AUTOSAR XML (schema 4-2-1)
# Copyright (c) 2017 Vector Informatik GmbH.
# License is restricted to the usage with CBD1601056 (D00) for MSR_Ford_SLP1.
# Please contact Vector Informatik whenever you need further information concerning the license conditions.
standard types defined: boolean, uint16, uint32, uint8
package /VehicleProject
  system System
package /TP
  can tp config HS2_CAN: communication-cluster=HS2_CAN, can-tp-ecu{cycle-time-main-function=0.005, ecu-instance=PSCM}
    can tp channel TPCH: channel-id=0, channel-mode=FULL-DUPLEX-MODE
    can-tp-connection addressing-format=STANDARD, can-tp-channel=TPCH, data-pdu=TesterFunctionalReq_H2_Tp_oHS2_CAN, receiver=TN_PSCM, ta-type=FUNCTIONAL, tp-sdu=TesterFunctionalReq_H2_oHS2_CAN, transmitter=TN_TSTR:
      ident TesterFunctionalReq_H2_oTN_TSTR
    can-tp-connection addressing-format=STANDARD, can-tp-channel=TPCH, data-pdu=TesterPhysicalReqPSCM_Tp_oHS2_CAN, flow-control-pdu=TesterPhysicalResPSCM_Tp_oHS2_CAN, receiver=TN_PSCM, ta-type=PHYSICAL, tp-sdu=TesterPhysicalReqPSCM_oHS2_CAN, transmitter=TN_TSTR:
      ident TesterPhysicalReqPSCM_oTN_PSCM
    can-tp-connection addressing-format=STANDARD, can-tp-channel=TPCH, data-pdu=TesterPhysicalResPSCM_Tp_oHS2_CAN, flow-control-pdu=TesterPhysicalReqPSCM_Tp_oHS2_CAN, receiver=TN_TSTR, ta-type=PHYSICAL, tp-sdu=TesterPhysicalResPSCM_oHS2_CAN, transmitter=TN_PSCM:
      ident TesterPhysicalResPSCM_oTN_PSCM
    can tp node TN_PSCM: connector=CN_HS2_CAN
    can tp node TN_TSTR
package /Cluster
  can cluster HS2_CAN: baudrate=500000, protocol-name=CAN  # Y2016_CGEA1.3_CMDB_B_v16.05_HS2 | CGEA1.3 HS2 CAN Network
    can physical channel CHNL: comm-connectors=CN_HS2_CAN
      frame ABS_AutoSar_Network_Mgmt_oHS2_CAN: id 0x596, to PSCM, frame-length=8, can-addressing-mode=STANDARD
        nm pdu ABS_AutoSar_Network_Mgmt_oHS2_CAN: length=8, unused-bit-pattern=0
      frame ABS_BrkBst_Data_oHS2_CAN: id 0x4B0, to PSCM, frame-length=8, can-addressing-mode=STANDARD
        pdu ABS_BrkBst_Data_oHS2_CAN: length=8, minimum-delay=0.01, transmission-mode-false-timing=cyclic-timing={time-offset=0, time-period=0.02}, transmission-mode-true-timing=cyclic-timing={time-offset=0, time-period=0.02}, unused-bit-pattern=0
          signal YawStabilityIndex_oABS_BrkBst_Data_oHS2_CAN: start 0, 9 bit, big-endian, init-value=256, base-type=uint16, compu {510=Cx1FE_NoDataExists, 511=Cx1FF_Fault, phys=raw-256 for raw 0..511; unit %}, unit=%, transfer-property=PENDING, to PSCM
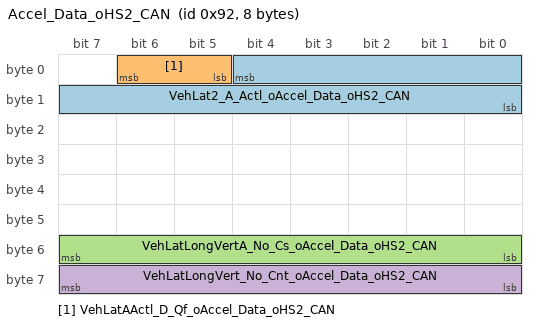
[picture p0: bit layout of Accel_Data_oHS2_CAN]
      frame Accel_Data_oHS2_CAN: id 0x92, to PSCM, frame-length=8, can-addressing-mode=STANDARD
        pdu Accel_Data_oHS2_CAN: length=8, minimum-delay=0, transmission-mode-false-timing=cyclic-timing={time-offset=0, time-period=0.01}, transmission-mode-true-timing=cyclic-timing={time-offset=0, time-period=0.01}, unused-bit-pattern=0
          signal VehLat2_A_Actl_oAccel_Data_oHS2_CAN: start 4, 13 bit, big-endian, init-value=8190, base-type=uint16, compu {8190=Cx1FFE_NoDataExists, 8191=Cx1FFF_Faulty, phys=raw*0.01-40 for raw 0..8191; unit m/s^2} "Source signal range: [0,8189]", unit=m/s^2, transfer-property=PENDING, to PSCM
          signal VehLatAActl_D_Qf_oAccel_Data_oHS2_CAN: start 6, 2 bit, big-endian, init-value=1, base-type=uint8, compu {0..3=RANGE, 0=Cx0_Faulty, 1=Cx1_No_Data_Exists, 2=Cx2_Not_Within_Specifications, 3=Cx3_OK; unit SED}, unit=SED, transfer-property=PENDING, to PSCM
          signal VehLatLongVertA_No_Cs_oAccel_Data_oHS2_CAN: start 55, 8 bit, big-endian, init-value=0, base-type=uint8, compu {0..255=RANGE; unit Unitless}, unit=Unitless, transfer-property=PENDING, to PSCM
          signal VehLatLongVert_No_Cnt_oAccel_Data_oHS2_CAN: start 63, 8 bit, big-endian, init-value=0, base-type=uint8, compu {0..255=RANGE; unit Unitless}, unit=Unitless, transfer-property=PENDING, to PSCM
      frame ActiveFrontSteering_Stat2_oHS2_CAN: id 0x8A, to PSCM, frame-length=8, can-addressing-mode=STANDARD
        pdu ActiveFrontSteering_Stat2_oHS2_CAN: length=8, minimum-delay=0, transmission-mode-false-timing=cyclic-timing={time-offset=0, time-period=0.01}, transmission-mode-true-timing=cyclic-timing={time-offset=0, time-period=0.01}, unused-bit-pattern=0
          signal SteWhlRelCalib_An_Sns_oActiveFrontSteering_Stat2_oHS2_CAN: start 15, 15 bit, big-endian, init-value=0, base-type=uint16, compu {32766=Cx7FFE_NoDataExists, 32767=Cx7FFF_Fault, phys=raw*0.1-1600 for raw 0..32767; unit deg} "Source signal range: [0,32765]", unit=deg, transfer-property=PENDING, to PSCM  # Signal is not transmitted on vehicles where PSCM is transmitting the message that contains this signal. Signal data set to 0x0 for ABS only vehicle option content
      frame Battery_Mgmt_2_HS2_oHS2_CAN: id 0x42C, to PSCM, frame-length=8, can-addressing-mode=STANDARD
        pdu Battery_Mgmt_2_HS2_oHS2_CAN: length=8, minimum-delay=0.02, transmission-mode-false-timing={cyclic-timing={time-offset=0, time-period=0.1}, event-controlled-timing={number-of-repetitions=0, repetition-period=0}}, transmission-mode-true-timing={cyclic-timing={time-offset=0, time-period=0.1}, event-controlled-timing={number-of-repetitions=0, repetition-period=0}}, unused-bit-pattern=0
          signal PwSysULoFalt_D_Stat_oBattery_Mgmt_2_HS2_oHS2_CAN: start 12, 4 bit, big-endian, init-value=0, base-type=uint8, compu {0..15=RANGE, 0=Cx0_No_Fault, 1=Cx1_Cluster_Proveout, 2=Cx2_Fault_Nonspecific, 3=Cx3_Fault_ReducedOutput, 4=Cx4_Fault_NoOutput, 5=Cx5_Overvoltage, 6=Cx6_LowBatt1_Warning, 7=Cx7_LowBatt2_PowerSaveMode, 8=Cx8_LowBattVoltDuringPwSrcOn, 9=Cx9_BattMonitoringSensorFault, 10=CxA_Not_Used_2, 11=CxB_Not_Used_3, 12=CxC_Not_Used_4, 13=CxD_PSS_Shed2_Contin, 14=CxE_LowBatterySOC, 15=CxF_Not_Used_6; unit SED}, unit=SED, transfer-property=TRIGGERED-ON-CHANGE-WITHOUT-REPETITION, to PSCM
      frame Body_Info_4_HS2_oHS2_CAN: id 0x242, to PSCM, frame-length=8, can-addressing-mode=STANDARD
        pdu Body_Info_4_HS2_oHS2_CAN: length=8, minimum-delay=0.02, transmission-mode-false-timing={cyclic-timing={time-offset=0, time-period=0.1}, event-controlled-timing={number-of-repetitions=0, repetition-period=0}}, transmission-mode-true-timing={cyclic-timing={time-offset=0, time-period=0.1}, event-controlled-timing={number-of-repetitions=0, repetition-period=0}}, unused-bit-pattern=0
          signal BattULo_U_Actl_oBody_Info_4_HS2_oHS2_CAN: start 39, 8 bit, big-endian, init-value=255, base-type=uint8, compu {255=CxFF_Fault, phys=raw*0.0625 for raw 0..255; unit volt} "Source signal range: [0,254]", unit=volt, transfer-property=PENDING, to PSCM
      frame BodyEngGateway_2_HS2_oHS2_CAN: id 0x431, to PSCM, frame-length=8, can-addressing-mode=STANDARD
        pdu BodyEngGateway_2_HS2_oHS2_CAN: length=8, minimum-delay=0.02, transmission-mode-false-timing={cyclic-timing={time-offset=0.1, time-period=1}, event-controlled-timing={number-of-repetitions=0, repetition-period=0}}, transmission-mode-true-timing={cyclic-timing={time-offset=0.1, time-period=1}, event-controlled-timing={number-of-repetitions=0, repetition-period=0}}, unused-bit-pattern=0
          signal SteEffort_D_Rq_oBodyEngGateway_2_HS2_oHS2_CAN: start 52, 3 bit, big-endian, init-value=0, base-type=uint8, compu {0..7=RANGE, 0=Cx0_Normal, 1=Cx1_Sport, 2=Cx2_Comfort, 3=Cx3_SpecialMode_1, 4=Cx4_SpecialMode_2, 5=Cx5_NotUsed_1, 6=Cx6_NotUsed_2, 7=Cx7_NotUsed_3; unit SED}, unit=SED, transfer-property=TRIGGERED-ON-CHANGE-WITHOUT-REPETITION, update-indication-bit-position=40, to PSCM
      frame BodyInfo_3_HS2_oHS2_CAN: id 0x3B3, to PSCM, frame-length=8, can-addressing-mode=STANDARD
        pdu BodyInfo_3_HS2_oHS2_CAN: length=8, minimum-delay=0.02, unused-bit-pattern=0
          signal Ignition_Status_oBodyInfo_3_HS2_oHS2_CAN: start 7, 4 bit, big-endian, init-value=0, base-type=uint8, compu {0..15=RANGE, 0=Cx0_Unknown, 1=Cx1_Off, 2=Cx2_Accessory, 4=Cx4_Run, 8=Cx8_Start, 15=CxF_Invalid; unit SED}, unit=SED, transfer-property=PENDING, to PSCM
          signal PrkBrkActv_B_Actl_oBodyInfo_3_HS2_oHS2_CAN: start 55, 1 bit, big-endian, init-value=0, base-type=boolean, compu {0..1=RANGE, 0=Cx0_Inactive, 1=Cx1_Active; unit SED}, unit=SED, transfer-property=PENDING, to PSCM  # Signal not transmitted on vehicles with electric park brake.
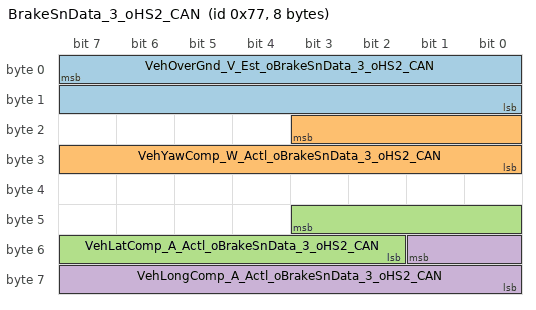
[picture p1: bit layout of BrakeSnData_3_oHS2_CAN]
      frame BrakeSnData_3_oHS2_CAN: id 0x77, to PSCM, frame-length=8, can-addressing-mode=STANDARD
        pdu BrakeSnData_3_oHS2_CAN: length=8, minimum-delay=0.01, transmission-mode-false-timing=cyclic-timing={time-offset=0, time-period=0.02}, transmission-mode-true-timing=cyclic-timing={time-offset=0, time-period=0.02}, unused-bit-pattern=0
          signal VehOverGnd_V_Est_oBrakeSnData_3_oHS2_CAN: start 7, 16 bit, big-endian, init-value=0, base-type=uint16, compu {65534=CxFFFE_Unknown, 65535=CxFFFF_Invalid, phys=raw*0.01 for raw 0..65535; unit kph} "Source signal range: [0,65533]", unit=kph, transfer-property=PENDING, to PSCM
          signal VehYawComp_W_Actl_oBrakeSnData_3_oHS2_CAN: start 19, 12 bit, big-endian, init-value=4094, base-type=uint16, compu {4094=CxFFE_NoDataExists, 4095=CxFFF_Fault, phys=raw*0.03663-75 for raw 0..4095; unit deg/s} "Source signal range: [0,4093]", unit=deg/s, transfer-property=PENDING, to PSCM
          signal VehLatComp_A_Actl_oBrakeSnData_3_oHS2_CAN: start 43, 10 bit, big-endian, init-value=1022, base-type=uint16, compu {1022=Cx3FE_NoDataExists, 1023=Cx3FF_Fault, phys=raw*0.035-17.9 for raw 0..1023; unit m/s^2} "Source signal range: [0,1021]", unit=m/s^2, transfer-property=PENDING, to PSCM
          signal VehLongComp_A_Actl_oBrakeSnData_3_oHS2_CAN: start 49, 10 bit, big-endian, init-value=1022, base-type=uint16, compu {1022=Cx3FE_NoDataExists, 1023=Cx3FF_Fault, phys=raw*0.035-17.9 for raw 0..1023; unit m/s^2} "Source signal range: [0,1021]", unit=m/s^2, transfer-property=PENDING, to PSCM
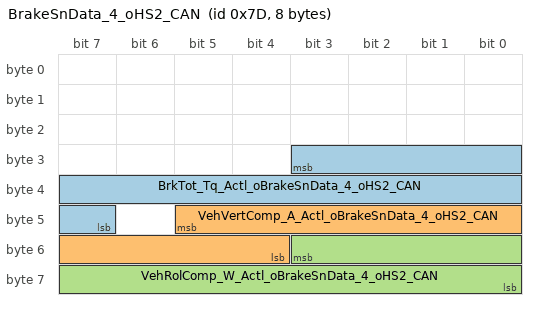
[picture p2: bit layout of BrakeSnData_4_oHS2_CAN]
      frame BrakeSnData_4_oHS2_CAN: id 0x7D, to PSCM, frame-length=8, can-addressing-mode=STANDARD
        pdu BrakeSnData_4_oHS2_CAN: length=8, minimum-delay=0.01, transmission-mode-false-timing=cyclic-timing={time-offset=0, time-period=0.02}, transmission-mode-true-timing=cyclic-timing={time-offset=0, time-period=0.02}, unused-bit-pattern=0
          signal BrkTot_Tq_Actl_oBrakeSnData_4_oHS2_CAN: start 27, 13 bit, big-endian, init-value=0, base-type=uint16, compu {8190=Cx1FFE_Unknown, 8191=Cx1FFF_Fault, phys=raw*4 for raw 0..8191; unit Nm} "Source signal range: [0,8189]", unit=Nm, transfer-property=PENDING, to PSCM
          signal VehVertComp_A_Actl_oBrakeSnData_4_oHS2_CAN: start 45, 10 bit, big-endian, init-value=1022, base-type=uint16, compu {1022=Cx3FE_NoDataExists, 1023=Cx3FF_Fault, phys=raw*0.035-17.9 for raw 0..1023; unit m/s^2} "Source signal range: [0,1021]", unit=m/s^2, transfer-property=PENDING, to PSCM
          signal VehRolComp_W_Actl_oBrakeSnData_4_oHS2_CAN: start 51, 12 bit, big-endian, init-value=4094, base-type=uint16, compu {4094=CxFFE_NoDataExists, 4095=CxFFF_Fault, phys=raw*0.03663-75 for raw 0..4095; unit degrees/sec} "Source signal range: [0,4093]", unit=degrees/sec, transfer-property=PENDING, to PSCM
      frame BrakeSnData_5_oHS2_CAN: id 0x76, to PSCM, frame-length=8, can-addressing-mode=STANDARD
        pdu BrakeSnData_5_oHS2_CAN: length=8, minimum-delay=0.02, transmission-mode-false-timing={cyclic-timing={time-offset=0, time-period=0.5}, event-controlled-timing={number-of-repetitions=0, repetition-period=0}}, transmission-mode-true-timing={cyclic-timing={time-offset=0, time-period=0.5}, event-controlled-timing={number-of-repetitions=0, repetition-period=0}}, unused-bit-pattern=0
          signal DrvSte_D_Stat_oBrakeSnData_5_oHS2_CAN: start 19, 4 bit, big-endian, init-value=0, base-type=uint8, compu {0..15=RANGE, 0=Cx0_DSR_Deactivated, 1=Cx1_DSR_Request_Not_Applicable, 2=Cx2_EPAS_Comm_Disturbed, 3=Cx3_DSR_in_Normal_Idle_Mode, 4=Cx4_Ignition_Off, 5=Cx5_Request_Active, 6=Cx6_NotUsed1, 7=Cx7_NotUsed2, 8=Cx8_NotUsed3, 9=Cx9_NotUsed4, 10=CxA_NotUsed5, 11=CxB_NotUsed6, 12=CxC_NotUsed7, 13=CxD_NotUsed8, 14=CxE_NotUsed9, 15=CxF_NotUsed10; unit SED}, unit=SED, transfer-property=TRIGGERED-ON-CHANGE-WITHOUT-REPETITION, to PSCM
          signal DrvSte_Tq_Rq_oBrakeSnData_5_oHS2_CAN: start 31, 8 bit, big-endian, init-value=128, base-type=uint8, compu {254=CxFE_Unknown, 255=CxFF_Invalid, phys=raw*0.0625-8 for raw 0..255; unit Nm} "Source signal range: [0,253]", unit=Nm, transfer-property=PENDING, to PSCM
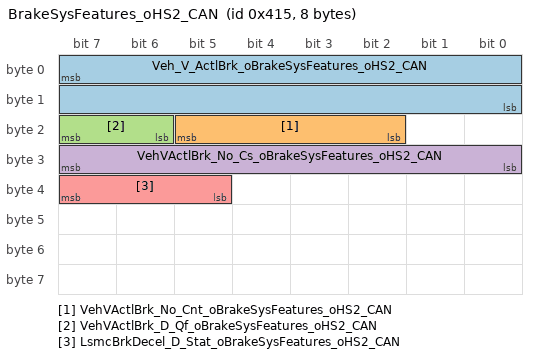
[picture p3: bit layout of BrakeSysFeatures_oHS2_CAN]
      frame BrakeSysFeatures_oHS2_CAN: id 0x415, to PSCM, frame-length=8, can-addressing-mode=STANDARD
        pdu BrakeSysFeatures_oHS2_CAN: length=8, minimum-delay=0.01, transmission-mode-false-timing=cyclic-timing={time-offset=0, time-period=0.02}, transmission-mode-true-timing=cyclic-timing={time-offset=0, time-period=0.02}, unused-bit-pattern=0
          signal Veh_V_ActlBrk_oBrakeSysFeatures_oHS2_CAN: start 7, 16 bit, big-endian, init-value=0, base-type=uint16, compu {phys=raw*0.01 for raw 0..65535; unit kph}, unit=kph, transfer-property=PENDING, to PSCM
          signal VehVActlBrk_No_Cnt_oBrakeSysFeatures_oHS2_CAN: start 21, 4 bit, big-endian, init-value=0, base-type=uint8, compu {0..15=RANGE; unit Unitless}, unit=Unitless, transfer-property=PENDING, to PSCM
          signal VehVActlBrk_D_Qf_oBrakeSysFeatures_oHS2_CAN: start 23, 2 bit, big-endian, init-value=0, base-type=uint8, compu {0..3=RANGE, 0=Cx0_Faulty, 1=Cx1_No_Data_Exists, 2=Cx2_Not_Within_Specifications, 3=Cx3_OK; unit SED}, unit=SED, transfer-property=PENDING, to PSCM
          signal VehVActlBrk_No_Cs_oBrakeSysFeatures_oHS2_CAN: start 31, 8 bit, big-endian, init-value=0, base-type=uint8, compu {0..255=RANGE; unit Unitless}, unit=Unitless, transfer-property=PENDING, to PSCM
          signal LsmcBrkDecel_D_Stat_oBrakeSysFeatures_oHS2_CAN: start 39, 3 bit, big-endian, init-value=0, base-type=uint8, compu {0..7=RANGE, 0=Cx0_Off, 1=Cx1_On, 2=Cx2_FaultExt, 3=Cx3_FaultDegraded, 4=Cx4_Denied, 5=Cx5_NotUsed_1, 6=Cx6_NotUsed_2, 7=Cx7_NotUsed_3; unit SED}, unit=SED, transfer-property=PENDING, to PSCM
      frame BrakeSysFeatures_2_oHS2_CAN: id 0x416, to PSCM, frame-length=8, can-addressing-mode=STANDARD
        pdu BrakeSysFeatures_2_oHS2_CAN: length=8, minimum-delay=0.02, transmission-mode-false-timing=cyclic-timing={time-offset=0, time-period=0.1}, transmission-mode-true-timing=cyclic-timing={time-offset=0, time-period=0.1}, unused-bit-pattern=0
          signal TCMode_oBrakeSysFeatures_2_oHS2_CAN: start 15, 1 bit, big-endian, init-value=0, base-type=boolean, compu {0..1=RANGE, 0=Cx0_Inactive, 1=Cx1_Active; unit SED}, unit=SED, transfer-property=PENDING, to PSCM  # Signal data set to 0x0 for ABS only vehicle option content
          signal DrvSlipCtlMde_D_Ind_oBrakeSysFeatures_2_oHS2_CAN: start 44, 2 bit, big-endian, init-value=0, base-type=uint8, compu {0..3=RANGE, 0=Cx0_Default_Mode, 1=Cx1_App_Specific_Off_Mode_1, 2=Cx2_App_Specific_Off_Mode_2, 3=Cx3_App_Specific_Off_Mode_3; unit SED}, unit=SED, transfer-property=PENDING, to PSCM
      frame BrakeSysFeatures_3_oHS2_CAN: id 0x41E, to PSCM, frame-length=8, can-addressing-mode=STANDARD
        pdu BrakeSysFeatures_3_oHS2_CAN: length=8, minimum-delay=0.02, transmission-mode-false-timing={cyclic-timing={time-offset=0, time-period=1}, event-controlled-timing={number-of-repetitions=0, repetition-period=0}}, transmission-mode-true-timing={cyclic-timing={time-offset=0, time-period=1}, event-controlled-timing={number-of-repetitions=0, repetition-period=0}}, unused-bit-pattern=0
          signal SelDrvMdeChassis_D_Rq_oBrakeSysFeatures_3_oHS2_CAN: start 39, 5 bit, big-endian, init-value=0, base-type=uint8, compu {0..31=RANGE, 0=Cx00_NormalMode, 1=Cx01_NormalAdaptiveMode, 2=Cx02_EconomyMode, 3=Cx03_SportMode, 4=Cx04_SportAdaptiveMode, 5=Cx05_ComfortMode, 6=Cx06_ComfortAdaptiveMode, 7=Cx07_LowMuMode, 8=Cx08_MudAndRutsMode, 9=Cx09_SandMode, 10=Cx0A_RockCrawlMode, 11=Cx0B_TowHaulMode, 12=Cx0C_HighSpeedDesertMode, 13=Cx0D_TrackMode, 14=Cx0E_NotUsed1, 15=Cx0F_NotUsed2, 16=Cx10_NotUsed3, 17=Cx11_NotUsed4, 18=Cx12_NotUsed5, 19=Cx13_NotUsed6, 20=Cx14_NotUsed7, 21=Cx15_NotUsed8, 22=Cx16_NotUsed9, 23=Cx17_NotUsed10, 24=Cx18_NotUsed11, 25=Cx19_NotUsed12, 26=Cx1A_NotUsed13, 27=Cx1B_NotUsed14, 28=Cx1C_NotUsed15, 29=Cx1D_NotUsed16, 30=Cx1E_NotUsed17, 31=Cx1F_Faulty; unit SED}, unit=SED, transfer-property=TRIGGERED-ON-CHANGE-WITHOUT-REPETITION, to PSCM
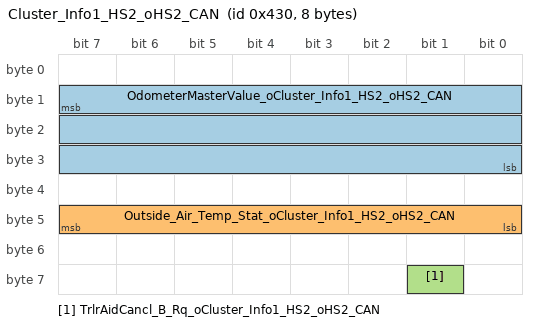
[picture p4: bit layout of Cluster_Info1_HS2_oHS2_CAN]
      frame Cluster_Info1_HS2_oHS2_CAN: id 0x430, to PSCM, frame-length=8, can-addressing-mode=STANDARD
        pdu Cluster_Info1_HS2_oHS2_CAN: length=8, minimum-delay=0.02, transmission-mode-false-timing={cyclic-timing={time-offset=0.2, time-period=0.1}, event-controlled-timing={number-of-repetitions=0, repetition-period=0}}, transmission-mode-true-timing={cyclic-timing={time-offset=0.2, time-period=0.1}, event-controlled-timing={number-of-repetitions=0, repetition-period=0}}, unused-bit-pattern=0
          signal OdometerMasterValue_oCluster_Info1_HS2_oHS2_CAN: start 15, 24 bit, big-endian, init-value=0, base-type=uint32, compu {0..16777215=RANGE, 16777215=CxFFFFFF_Invalid; unit km} "Source signal range: [0,16777214]", unit=km, transfer-property=TRIGGERED-ON-CHANGE-WITHOUT-REPETITION, update-indication-bit-position=0, to PSCM
          signal Outside_Air_Temp_Stat_oCluster_Info1_HS2_oHS2_CAN: start 47, 8 bit, big-endian, init-value=254, base-type=uint8, compu {254=CxFE_Unknown, 255=CxFF_Invalid, phys=raw*0.5-40 for raw 0..255; unit Degrees C} "Source signal range: [0,253]", unit=Degrees C, transfer-property=TRIGGERED-ON-CHANGE-WITHOUT-REPETITION, update-indication-bit-position=3, to PSCM  # Filtered value, i.e. same as disply for customer
          signal TrlrAidCancl_B_Rq_oCluster_Info1_HS2_oHS2_CAN: start 57, 1 bit, big-endian, init-value=0, base-type=boolean, compu {0..1=RANGE, 0=Cx0_Null, 1=Cx1_Cancel; unit SED}, unit=SED, transfer-property=TRIGGERED-ON-CHANGE-WITHOUT-REPETITION, update-indication-bit-position=56, to PSCM
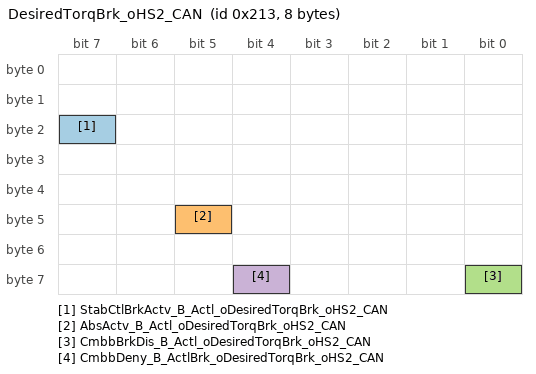
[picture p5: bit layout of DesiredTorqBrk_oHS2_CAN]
      frame DesiredTorqBrk_oHS2_CAN: id 0x213, to PSCM, frame-length=8, can-addressing-mode=STANDARD  # When PBM is present use 0x41B for PrkMsgTxt_D_Rq, PrkBrkRedLamp_D_Rq, PrkBrkYwLamp_D_Rq source signals otherwise ABS will source from 0x213.
        pdu DesiredTorqBrk_oHS2_CAN: length=8, minimum-delay=0.01, transmission-mode-false-timing=cyclic-timing={time-offset=0, time-period=0.02}, transmission-mode-true-timing=cyclic-timing={time-offset=0, time-period=0.02}, unused-bit-pattern=0
          signal StabCtlBrkActv_B_Actl_oDesiredTorqBrk_oHS2_CAN: start 23, 1 bit, big-endian, init-value=0, base-type=boolean, compu {0..1=RANGE, 0=Cx0_No, 1=Cx1_Yes; unit SED}, unit=SED, transfer-property=PENDING, to PSCM
          signal AbsActv_B_Actl_oDesiredTorqBrk_oHS2_CAN: start 45, 1 bit, big-endian, init-value=0, base-type=boolean, compu {0..1=RANGE, 0=Cx0_No, 1=Cx1_Yes; unit SED}, unit=SED, transfer-property=PENDING, to PSCM
          signal CmbbBrkDis_B_Actl_oDesiredTorqBrk_oHS2_CAN: start 56, 1 bit, big-endian, init-value=0, base-type=boolean, compu {0..1=RANGE, 0=Cx0_No, 1=Cx1_Yes; unit SED}, unit=SED, transfer-property=PENDING, to PSCM
          signal CmbbDeny_B_ActlBrk_oDesiredTorqBrk_oHS2_CAN: start 60, 1 bit, big-endian, init-value=0, base-type=boolean, compu {0..1=RANGE, 0=Cx0_No, 1=Cx1_Yes; unit SED}, unit=SED, transfer-property=PENDING, to PSCM
      frame Driveline_Data_1_oHS2_CAN: id 0x263, to PSCM, frame-length=8, can-addressing-mode=STANDARD  # Used on Applications with 4x4 supplied by Motorola.
        pdu Driveline_Data_1_oHS2_CAN: length=8, minimum-delay=0.02, transmission-mode-false-timing=cyclic-timing={time-offset=0, time-period=0.1}, transmission-mode-true-timing=cyclic-timing={time-offset=0, time-period=0.1}, unused-bit-pattern=0
          signal AwdRnge_D_Actl_oDriveline_Data_1_oHS2_CAN: start 7, 3 bit, big-endian, init-value=7, base-type=uint8, compu {0..7=RANGE, 0=Cx0_Low_Range_Locked, 1=Cx1_Low_Range_Auto, 2=Cx2_Low_Range_2wd, 3=Cx3_Neutral, 4=Cx4_High_Range_Locked, 5=Cx5_High_Range_Auto, 6=Cx6_High_Range_2wd, 7=Cx7_Unknown; unit SED}, unit=SED, transfer-property=PENDING, to PSCM
          signal AwdDrvMde_D_Stat_oDriveline_Data_1_oHS2_CAN: start 38, 3 bit, big-endian, init-value=0, base-type=uint8, compu {0..7=RANGE, 0=Cx0_Normal, 1=Cx1_Sport, 2=Cx2_Weather, 3=Cx3_MudAndSand, 4=Cx4_Baja, 5=Cx5_RockCrawl, 6=Cx6_NotAvailable, 7=Cx7_Faulty; unit SED}, unit=SED, transfer-property=PENDING, to PSCM
      frame EngBrakeData_HS2_oHS2_CAN: id 0x165, to PSCM, frame-length=8, can-addressing-mode=STANDARD
        pdu EngBrakeData_HS2_oHS2_CAN: length=8, minimum-delay=0.01, transmission-mode-false-timing={cyclic-timing={time-offset=0, time-period=0.1}, event-controlled-timing={number-of-repetitions=0, repetition-period=0}}, transmission-mode-true-timing={cyclic-timing={time-offset=0, time-period=0.1}, event-controlled-timing={number-of-repetitions=0, repetition-period=0}}, unused-bit-pattern=0
          signal BpedDrvAppl_D_Actl_oEngBrakeData_HS2_oHS2_CAN: start 5, 2 bit, big-endian, init-value=1, base-type=uint8, compu {0..3=RANGE, 0=Cx0_Not_Allowed, 1=Cx1_Driver_Not_Braking, 2=Cx2_Driver_Braking, 3=Cx3_Not_Allowed; unit SED}, unit=SED, transfer-property=TRIGGERED-ON-CHANGE-WITHOUT-REPETITION, to PSCM  # CCMGenSigTimeoutTime=1000
          signal BPedDrvAppl_D_QF_oEngBrakeData_HS2_oHS2_CAN: start 15, 2 bit, big-endian, init-value=1, base-type=uint8, compu {0..3=RANGE, 0=Cx0_Faulty, 1=Cx1_No_Data_Exists, 2=Cx2_Not_Within_Specifications, 3=Cx3_OK; unit SED}, unit=SED, transfer-property=TRIGGERED-ON-CHANGE-WITHOUT-REPETITION, to PSCM
      frame EngineData_9_HS2_oHS2_CAN: id 0x78, to PSCM, frame-length=8, can-addressing-mode=STANDARD
        pdu EngineData_9_HS2_oHS2_CAN: length=8, minimum-delay=0.01, transmission-mode-false-timing=cyclic-timing={time-offset=0, time-period=0.05}, transmission-mode-true-timing=cyclic-timing={time-offset=0, time-period=0.05}, unused-bit-pattern=0
          signal TrlrAidSwtch_D_RqDrv_oEngineData_9_HS2_oHS2_CAN: start 22, 2 bit, big-endian, init-value=0, base-type=uint8, compu {0..3=RANGE, 0=Cx0_Not_Pressed, 1=Cx1_Pressed, 2=Cx2_NotUsed, 3=Cx3_Faulty; unit SED}, unit=SED, transfer-property=PENDING, update-indication-bit-position=20, to PSCM
          signal TrlrAidCtl_U_RqDrv_oEngineData_9_HS2_oHS2_CAN: start 27, 12 bit, big-endian, init-value=4094, base-type=uint16, compu {4094=CxFFE_NoDataExists, 4095=CxFFF_Faulty, phys=raw/800 for raw 0..4095; unit volt} "Source signal range: [0,4093]", unit=volt, transfer-property=PENDING, update-indication-bit-position=31, to PSCM
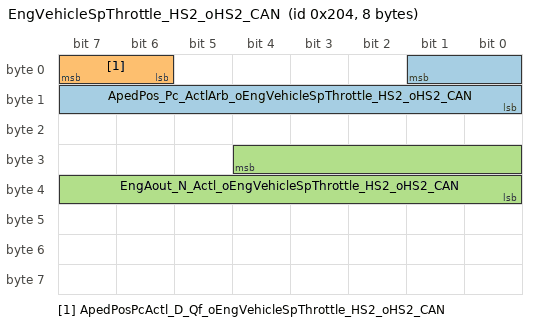
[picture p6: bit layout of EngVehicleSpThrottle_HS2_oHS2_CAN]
      frame EngVehicleSpThrottle_HS2_oHS2_CAN: id 0x204, to PSCM, frame-length=8, can-addressing-mode=STANDARD
        pdu EngVehicleSpThrottle_HS2_oHS2_CAN: length=8, minimum-delay=0.005, unused-bit-pattern=0
          signal ApedPos_Pc_ActlArb_oEngVehicleSpThrottle_HS2_oHS2_CAN: start 1, 10 bit, big-endian, init-value=0, base-type=uint16, compu {phys=raw*0.1 for raw 0..1022; unit %}, unit=%, transfer-property=PENDING, to PSCM  # ABSGenSigTimeoutTime=1000
          signal ApedPosPcActl_D_Qf_oEngVehicleSpThrottle_HS2_oHS2_CAN: start 7, 2 bit, big-endian, init-value=1, base-type=uint8, compu {0..3=RANGE, 0=Cx0_Faulty, 1=Cx1_No_Data_Exists, 2=Cx2_Not_Within_Specifications, 3=Cx3_OK; unit SED}, unit=SED, transfer-property=PENDING, to PSCM
          signal EngAout_N_Actl_oEngVehicleSpThrottle_HS2_oHS2_CAN: start 28, 13 bit, big-endian, init-value=0, base-type=uint16, compu {phys=raw*2 for raw 0..8191; unit rpm}, unit=rpm, transfer-property=PENDING, to PSCM
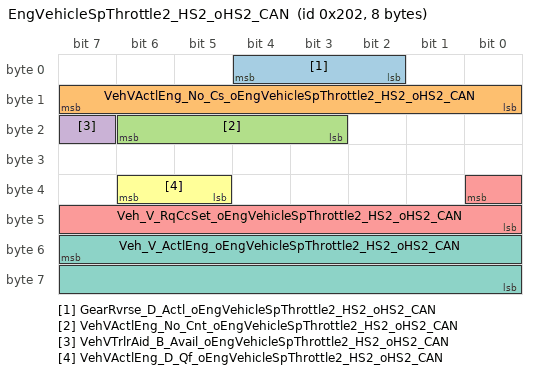
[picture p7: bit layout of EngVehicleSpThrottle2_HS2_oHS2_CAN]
      frame EngVehicleSpThrottle2_HS2_oHS2_CAN: id 0x202, to PSCM, frame-length=8, can-addressing-mode=STANDARD
        pdu EngVehicleSpThrottle2_HS2_oHS2_CAN: length=8, minimum-delay=0.005, unused-bit-pattern=0
          signal GearRvrse_D_Actl_oEngVehicleSpThrottle2_HS2_oHS2_CAN: start 4, 3 bit, big-endian, init-value=7, base-type=uint8, compu {0..7=RANGE, 0=Cx0_Inactive_not_confirmed, 1=Cx1_Inactive_confirmed, 2=Cx2_Active_not_confirmed, 3=Cx3_Active_confirmed, 4=Cx4_NotUsed_1, 5=Cx5_NotUsed_2, 6=Cx6_NotUsed_3, 7=Cx7_Fault; unit SED}, unit=SED, transfer-property=PENDING, to PSCM  # Do not implement GearRvrse_D_Actl until eTracker 8804151 is approved, 11/24/09
          signal VehVActlEng_No_Cs_oEngVehicleSpThrottle2_HS2_oHS2_CAN: start 15, 8 bit, big-endian, init-value=0, base-type=uint8, compu {0..255=RANGE; unit Unitless}, unit=Unitless, transfer-property=PENDING, to PSCM
          signal VehVActlEng_No_Cnt_oEngVehicleSpThrottle2_HS2_oHS2_CAN: start 22, 4 bit, big-endian, init-value=0, base-type=uint8, compu {0..15=RANGE; unit Unitless}, unit=Unitless, transfer-property=PENDING, to PSCM
          signal VehVTrlrAid_B_Avail_oEngVehicleSpThrottle2_HS2_oHS2_CAN: start 23, 1 bit, big-endian, init-value=0, base-type=boolean, compu {0..1=RANGE, 0=Cx0_No, 1=Cx1_Yes; unit SED}, unit=SED, transfer-property=PENDING, to PSCM
          signal Veh_V_RqCcSet_oEngVehicleSpThrottle2_HS2_oHS2_CAN: start 32, 9 bit, big-endian, init-value=0, base-type=uint16, compu {phys=raw*0.5 for raw 0..511; unit kph}, unit=kph, transfer-property=PENDING, to PSCM
          signal VehVActlEng_D_Qf_oEngVehicleSpThrottle2_HS2_oHS2_CAN: start 38, 2 bit, big-endian, init-value=0, base-type=uint8, compu {0..3=RANGE, 0=Cx0_Faulty, 1=Cx1_No_Data_Exists, 2=Cx2_Not_Within_Specifications, 3=Cx3_OK; unit SED}, unit=SED, transfer-property=PENDING, to PSCM
          signal Veh_V_ActlEng_oEngVehicleSpThrottle2_HS2_oHS2_CAN: start 55, 16 bit, big-endian, init-value=0, base-type=uint16, compu {phys=raw*0.01 for raw 0..65535; unit kph}, unit=kph, transfer-property=PENDING, to PSCM
      frame EPAS_INFO_oHS2_CAN: id 0x82, from PSCM, frame-length=8, can-addressing-mode=STANDARD  # drecker 10/23/09 Need SAPP in sync w/Strg Torque for proper PAM interpretation, else fault msg's displayed FP@20ms IPC needs EPAS_Failure for msg to driver. Not map w/Lane Assist FP@30s FP), save bandwidth if feature not on vehicle
        pdu EPAS_INFO_oHS2_CAN: length=8, minimum-delay=0.01, transmission-mode-false-timing=cyclic-timing={time-offset=0, time-period=0.02}, transmission-mode-true-timing=cyclic-timing={time-offset=0, time-period=0.02}, unused-bit-pattern=0
          signal SteeringColumnTorque_oEPAS_INFO_oHS2_CAN: start 7, 8 bit, big-endian, init-value=254, base-type=uint8, compu {254=CxFE_Unknown, 255=CxFF_Invalid, phys=raw*0.0625-8 for raw 0..255; unit Nm} "Source signal range: [0,253]", unit=Nm, transfer-property=PENDING
          signal EPAS_Failure_oEPAS_INFO_oHS2_CAN: start 9, 2 bit, big-endian, init-value=0, base-type=uint8, compu {0..3=RANGE, 0=Cx0_EPAS_OK_NO_MESSAGE, 1=Cx1_POWER_STRG_ASSIST_FAULT, 2=Cx2_SERVICE_POWER_STEERING, 3=Cx3_SERVICE_POWER_STEERING_NOW; unit SED}, unit=SED, transfer-property=PENDING
          signal DrvSteActv_B_Stat_oEPAS_INFO_oHS2_CAN: start 10, 1 bit, big-endian, init-value=0, base-type=boolean, compu {0..1=RANGE, 0=Cx0_Inactive, 1=Cx1_Active; unit SED}, unit=SED, transfer-property=PENDING
          signal SAPPAngleControlStat2_oEPAS_INFO_oHS2_CAN: start 11, 1 bit, big-endian, init-value=0, base-type=boolean, compu {0..1=RANGE, 0=Cx0_NoRel_ExtSteeringAngleReqx, 1=Cx1_Rel_ExtSteeringAngleReqx; unit SED}, unit=SED, transfer-property=PENDING
          signal SAPPAngleControlStat3_oEPAS_INFO_oHS2_CAN: start 12, 1 bit, big-endian, init-value=0, base-type=boolean, compu {0..1=RANGE, 0=Cx0_ExternalSigContentOKforEAC, 1=Cx1_EARactiveNoReverseEngage; unit SED}, unit=SED, transfer-property=PENDING
          signal SAPPAngleControlStat4_oEPAS_INFO_oHS2_CAN: start 13, 1 bit, big-endian, init-value=0, base-type=boolean, compu {0..1=RANGE, 0=Cx0_ExternalSigContentOKforEAC, 1=Cx1_SpeedLimitExceededEAROn; unit SED}, unit=SED, transfer-property=PENDING
          signal SAPPAngleControlStat5_oEPAS_INFO_oHS2_CAN: start 14, 1 bit, big-endian, init-value=0, base-type=boolean, compu {0..1=RANGE, 0=Cx0_ExternalSigContentOKforEAC, 1=Cx1_StrgColTorqueExceed_EAROn; unit SED}, unit=SED, transfer-property=PENDING
          signal SAPPAngleControlStat6_oEPAS_INFO_oHS2_CAN: start 15, 1 bit, big-endian, init-value=0, base-type=boolean, compu {0..1=RANGE, 0=Cx0_RequestedAngleCanBeReached, 1=Cx1_RequestedAngleNotReached; unit SED}, unit=SED, transfer-property=PENDING
          signal SteMdule_I_Est_oEPAS_INFO_oHS2_CAN: start 21, 12 bit, big-endian, init-value=4095, base-type=uint16, compu {4095=CxFFF_Invalid, phys=raw*0.05-64 for raw 0..4095; unit Amps} "Source signal range: [0,4094]", unit=Amps, transfer-property=PENDING  # DCR 1745 to update Tx from GWM to EP100ms. SteMdule_I_Est & SteMdule_U_Meas are used by BMS system & filtered. The filter uses standard periodic rate & changing to EP would adversely affect the filter.(jweinfur)
          signal SAPPAngleControlStat1_oEPAS_INFO_oHS2_CAN: start 23, 2 bit, big-endian, init-value=0, base-type=uint8, compu {0..3=RANGE, 0=Cx0_Closed, 1=Cx1_Open, 2=Cx2_Active, 3=Cx3_Fault; unit SED}, unit=SED, transfer-property=PENDING
          signal TrlrHitchLamp_D_Rqst_oEPAS_INFO_oHS2_CAN: start 24, 1 bit, big-endian, init-value=0, base-type=boolean, compu {0..1=RANGE, 0=Cx0_Off, 1=Cx1_On; unit SED}, unit=SED, transfer-property=PENDING
          signal VehVTrlrAid_B_Rq_oEPAS_INFO_oHS2_CAN: start 25, 1 bit, big-endian, init-value=0, base-type=boolean, compu {0..1=RANGE, 0=Cx0_NoRequest, 1=Cx1_Request; unit SED}, unit=SED, transfer-property=PENDING  # VR session start- req. limit blower speed no more than X volts. CC restriction on time msg. will be honored.Double Event msg1st event to request limit, 2nd event to release limit, No msg. CC Grammar v7.xls
          signal SteMdule_U_Meas_oEPAS_INFO_oHS2_CAN: start 39, 8 bit, big-endian, init-value=255, base-type=uint8, compu {255=CxFF_Invalid, phys=raw*0.05+6 for raw 0..255; unit Volts} "Source signal range: [0,254]", unit=Volts, transfer-property=PENDING  # DCR 1745 to update Tx from GWM to EP100ms. SteMdule_I_Est & SteMdule_U_Meas are used by BMS system & filtered. The filter uses standard periodic rate & changing to EP would adversely affect the filter.(jweinfur)
          signal DrvSte_Tq_Actl_oEPAS_INFO_oHS2_CAN: start 47, 8 bit, big-endian, init-value=128, base-type=uint8, compu {254=CxFE_Unknown, 255=CxFF_Invalid, phys=raw*0.0625-8 for raw 0..255; unit Nm} "Source signal range: [0,253]", unit=Nm, transfer-property=PENDING
          signal SteEffort_D_Stat_oEPAS_INFO_oHS2_CAN: start 52, 3 bit, big-endian, init-value=0, base-type=uint8, compu {0..7=RANGE, 0=Cx0_Normal, 1=Cx1_Sport, 2=Cx2_Comfort, 3=Cx3_SpecialMode_1, 4=Cx4_SpecialMode_2, 5=Cx5_NotUsed_1, 6=Cx6_NotUsed_2, 7=Cx7_NotUsed_3; unit SED}, unit=SED, transfer-property=PENDING
          signal SteMdule_D_Stat_oEPAS_INFO_oHS2_CAN: start 55, 3 bit, big-endian, init-value=0, base-type=uint8, compu {0..7=RANGE, 0=Cx0_EPAS_Initialization, 1=Cx1_Normal_Op_Limited_Assist, 2=Cx2_Normal_Op_Full_Assist, 3=Cx3_EPAS_Shutdown, 4=Cx4_System_Failure, 5=Cx5_EPAS_Failure2, 6=Cx6_EPAS_Failure3, 7=Cx7_NotUsed; unit SED}, unit=SED, transfer-property=PENDING
          signal Veh_V_RqMxTrlrAid_oEPAS_INFO_oHS2_CAN: start 63, 8 bit, big-endian, init-value=255, base-type=uint8, compu {phys=raw*0.1 for raw 0..255; unit km/h}, unit=km/h, transfer-property=PENDING
      frame GatewayData_HS2_oHS2_CAN: id 0x43A, to PSCM, frame-length=8, can-addressing-mode=STANDARD
        pdu GatewayData_HS2_oHS2_CAN: length=8, minimum-delay=0.02, transmission-mode-false-timing={cyclic-timing={time-offset=0, time-period=1}, event-controlled-timing={number-of-repetitions=0, repetition-period=0}}, transmission-mode-true-timing={cyclic-timing={time-offset=0, time-period=1}, event-controlled-timing={number-of-repetitions=0, repetition-period=0}}, unused-bit-pattern=0
          signal EsaOn_B_Rq_oGatewayData_HS2_oHS2_CAN: start 34, 1 bit, big-endian, init-value=1, base-type=boolean, compu {0..1=RANGE, 0=Cx0_Off, 1=Cx1_On; unit SED}, unit=SED, transfer-property=TRIGGERED-ON-CHANGE-WITHOUT-REPETITION, update-indication-bit-position=33, to PSCM
      frame GatewayData3_HS2_oHS2_CAN: id 0x438, to PSCM, frame-length=8, can-addressing-mode=STANDARD
        pdu GatewayData3_HS2_oHS2_CAN: length=8, minimum-delay=0.02, transmission-mode-false-timing={cyclic-timing={time-offset=0, time-period=1}, event-controlled-timing={number-of-repetitions=0, repetition-period=0}}, transmission-mode-true-timing={cyclic-timing={time-offset=0, time-period=1}, event-controlled-timing={number-of-repetitions=0, repetition-period=0}}, unused-bit-pattern=0
          signal TurnLghtSwtch_D_Stat2_oGatewayData3_HS2_oHS2_CAN: start 3, 2 bit, big-endian, init-value=0, base-type=uint8, compu {0..3=RANGE, 0=Cx0_Off, 1=Cx1_Left, 2=Cx2_Right, 3=Cx3_NotUsed; unit SED}, unit=SED, transfer-property=TRIGGERED-ON-CHANGE-WITHOUT-REPETITION, update-indication-bit-position=1, to PSCM
      frame GGCC_Config_Mgmt_ID_1_HS2_oHS2_CAN: id 0x40A, to PSCM, frame-length=8, can-addressing-mode=STANDARD
        pdu GGCC_Config_Mgmt_ID_1_HS2_oHS2_CAN: length=8, minimum-delay=0.02, unused-bit-pattern=0
          signal VehicleGGCCData_oGGCC_Config_Mgmt_ID_1_HS2_oHS2_CAN: start 0, 64 bit, opaque, init-value=8 x 0, base-type=uint8_8_iso_8859_1, compu {0..18446744073709551615=RANGE; unit mixed}, unit=mixed, transfer-property=PENDING, to PSCM  # RCMGenSigTimeout=6000
      frame GWM_AutoSar_NetMgmt_HS2_oHS2_CAN: id 0x59E, to PSCM, frame-length=8, can-addressing-mode=STANDARD
        nm pdu GWM_AutoSar_NetMgmt_HS2_oHS2_CAN: length=8, unused-bit-pattern=0
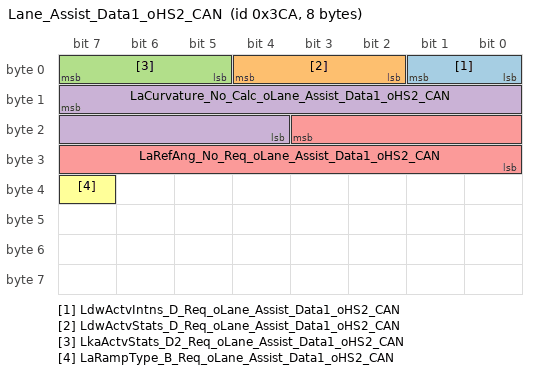
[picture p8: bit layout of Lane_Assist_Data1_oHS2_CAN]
      frame Lane_Assist_Data1_oHS2_CAN: id 0x3CA, to PSCM, frame-length=8, can-addressing-mode=STANDARD
        pdu Lane_Assist_Data1_oHS2_CAN: length=8, minimum-delay=0.01, transmission-mode-false-timing=cyclic-timing={time-offset=0, time-period=0.03}, transmission-mode-true-timing=cyclic-timing={time-offset=0, time-period=0.03}, unused-bit-pattern=0
          signal LdwActvIntns_D_Req_oLane_Assist_Data1_oHS2_CAN: start 1, 2 bit, big-endian, init-value=0, base-type=uint8, compu {0..3=RANGE, 0=Cx0_None, 1=Cx1_Low, 2=Cx2_Medium, 3=Cx3_High; unit SED}, unit=SED, transfer-property=PENDING, to PSCM
          signal LdwActvStats_D_Req_oLane_Assist_Data1_oHS2_CAN: start 4, 3 bit, big-endian, init-value=0, base-type=uint8, compu {0..7=RANGE, 0=Cx0_LDW_Idle, 1=Cx1_Not_Used1, 2=Cx2_LDW_Warning_Left, 3=Cx3_LDW_Suppress_Left, 4=Cx4_LDW_Warning_Right, 5=Cx5_LDW_Suppress_Right, 6=Cx6_Not_Used2, 7=Cx7_LDW_Suppress_Right_Left; unit SED}, unit=SED, transfer-property=PENDING, to PSCM
          signal LkaActvStats_D2_Req_oLane_Assist_Data1_oHS2_CAN: start 7, 3 bit, big-endian, init-value=0, base-type=uint8, compu {0..7=RANGE, 0=Cx0_LkaNoInterv, 1=Cx1_LkaIncrIntervLeft, 2=Cx2_LkaStandIntervLeft, 3=Cx3_LkaSupprLeft, 4=Cx4_LkaStandIntervRight, 5=Cx5_LkaSupprRight, 6=Cx6_LkaIncrIntervRight, 7=Cx7_NotUsed; unit SED}, unit=SED, transfer-property=PENDING, to PSCM
          signal LaCurvature_No_Calc_oLane_Assist_Data1_oHS2_CAN: start 15, 12 bit, big-endian, init-value=2048, base-type=uint16, compu {4095=CxFFF_Fault, phys=raw*5e-06-0.01024 for raw 0..4095; unit 1/m} "Source signal range: [0,4094]", unit=1/m, transfer-property=PENDING, to PSCM
          signal LaRefAng_No_Req_oLane_Assist_Data1_oHS2_CAN: start 19, 12 bit, big-endian, init-value=2048, base-type=uint16, compu {4095=CxFFF_Fault, phys=raw*0.05-102.4 for raw 0..4095; unit mrad} "Source signal range: [0,4094]", unit=mrad, transfer-property=PENDING, to PSCM
          signal LaRampType_B_Req_oLane_Assist_Data1_oHS2_CAN: start 39, 1 bit, big-endian, init-value=0, base-type=boolean, compu {0..1=RANGE, 0=Cx0_Smooth, 1=Cx1_Quick; unit SED}, unit=SED, transfer-property=PENDING, to PSCM
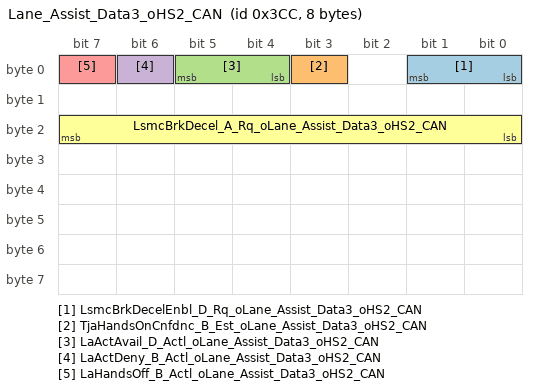
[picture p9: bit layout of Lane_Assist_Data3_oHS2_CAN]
      frame Lane_Assist_Data3_oHS2_CAN: id 0x3CC, from PSCM, frame-length=8, can-addressing-mode=STANDARD
        pdu Lane_Assist_Data3_oHS2_CAN: length=8, minimum-delay=0.01, transmission-mode-false-timing=cyclic-timing={time-offset=0, time-period=0.03}, transmission-mode-true-timing=cyclic-timing={time-offset=0, time-period=0.03}, unused-bit-pattern=0
          signal LsmcBrkDecelEnbl_D_Rq_oLane_Assist_Data3_oHS2_CAN: start 1, 2 bit, big-endian, init-value=0, base-type=uint8, compu {0..3=RANGE, 0=Cx0_Off, 1=Cx1_On, 2=Cx2_NotUsed1, 3=Cx3_NotUsed2; unit SED}, unit=SED, transfer-property=PENDING
          signal TjaHandsOnCnfdnc_B_Est_oLane_Assist_Data3_oHS2_CAN: start 3, 1 bit, big-endian, init-value=1, base-type=boolean, compu {0..1=RANGE, 0=Cx0_Low_Confidence, 1=Cx1_High_Confidence; unit SED}, unit=SED, transfer-property=PENDING
          signal LaActAvail_D_Actl_oLane_Assist_Data3_oHS2_CAN: start 5, 2 bit, big-endian, init-value=0, base-type=uint8, compu {0..3=RANGE, 0=Cx0_LCA_LKA_LDW_Suppress, 1=Cx1_LCA_LKA_Suppress_LDW_Avail, 2=Cx2_LCA_LKA_Avail_LDW_Suppress, 3=Cx3_LKA_LCA_LDW_Avail; unit SED}, unit=SED, transfer-property=PENDING
          signal LaActDeny_B_Actl_oLane_Assist_Data3_oHS2_CAN: start 6, 1 bit, big-endian, init-value=0, base-type=boolean, compu {0..1=RANGE, 0=Cx0_LA_Not_Denied, 1=Cx1_LA_Denied; unit SED}, unit=SED, transfer-property=PENDING
          signal LaHandsOff_B_Actl_oLane_Assist_Data3_oHS2_CAN: start 7, 1 bit, big-endian, init-value=1, base-type=boolean, compu {0..1=RANGE, 0=Cx0_Hands_On, 1=Cx1_Hands_Off; unit SED}, unit=SED, transfer-property=PENDING
          signal LsmcBrkDecel_A_Rq_oLane_Assist_Data3_oHS2_CAN: start 23, 8 bit, big-endian, init-value=0, base-type=uint8, compu {phys=raw*0.1 for raw 0..255; unit m/s^2}, unit=m/s^2, transfer-property=PENDING
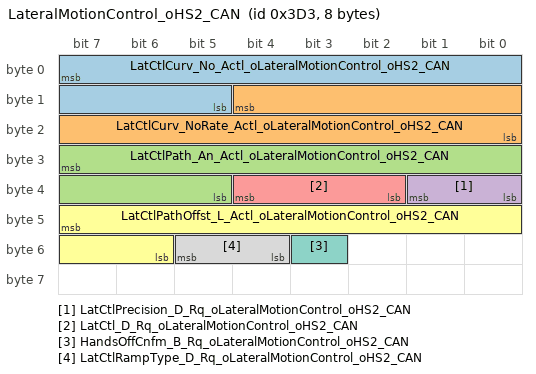
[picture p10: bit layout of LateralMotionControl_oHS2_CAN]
      frame LateralMotionControl_oHS2_CAN: id 0x3D3, to PSCM, frame-length=8, can-addressing-mode=STANDARD
        pdu LateralMotionControl_oHS2_CAN: length=8, minimum-delay=0.02, transmission-mode-false-timing=cyclic-timing={time-offset=0, time-period=0.05}, transmission-mode-true-timing=cyclic-timing={time-offset=0, time-period=0.05}, unused-bit-pattern=0
          signal LatCtlCurv_No_Actl_oLateralMotionControl_oHS2_CAN: start 7, 11 bit, big-endian, init-value=1000, base-type=uint16, compu {phys=raw*2e-05-0.02 for raw 0..2047; unit 1/meter}, unit=1/meter, transfer-property=PENDING, to PSCM
          signal LatCtlCurv_NoRate_Actl_oLateralMotionControl_oHS2_CAN: start 12, 13 bit, big-endian, init-value=4096, base-type=uint16, compu {phys=raw/4000000-0.001024 for raw 0..8191; unit 1/meter}, unit=1/meter, transfer-property=PENDING, to PSCM
          signal LatCtlPath_An_Actl_oLateralMotionControl_oHS2_CAN: start 31, 11 bit, big-endian, init-value=1000, base-type=uint16, compu {phys=raw*0.0005-0.5 for raw 0..2046; unit radians}, unit=radians, transfer-property=PENDING, to PSCM
          signal LatCtlPrecision_D_Rq_oLateralMotionControl_oHS2_CAN: start 33, 2 bit, big-endian, init-value=0, base-type=uint8, compu {0..3=RANGE, 0=Cx0_Comfortable, 1=Cx1_Precise, 2=Cx2_NotUsed1, 3=Cx3_NotUsed2; unit SED}, unit=SED, transfer-property=PENDING, to PSCM
          signal LatCtl_D_Rq_oLateralMotionControl_oHS2_CAN: start 36, 3 bit, big-endian, init-value=0, base-type=uint8, compu {0..7=RANGE, 0=Cx0_NoLateralControl, 1=Cx1_ContinuousPathFollowing, 2=Cx2_InterventionLeft, 3=Cx3_InterventionRight, 4=Cx4_NotUsed1, 5=Cx5_NotUsed2, 6=Cx6_NotUsed3, 7=Cx7_NotUsed4; unit SED}, unit=SED, transfer-property=PENDING, to PSCM
          signal LatCtlPathOffst_L_Actl_oLateralMotionControl_oHS2_CAN: start 47, 10 bit, big-endian, init-value=512, base-type=uint16, compu {phys=raw*0.01-5.12 for raw 0..1023; unit meter}, unit=meter, transfer-property=PENDING, to PSCM
          signal HandsOffCnfm_B_Rq_oLateralMotionControl_oHS2_CAN: start 51, 1 bit, big-endian, init-value=0, base-type=boolean, compu {0..1=RANGE, 0=Cx0_Inactive, 1=Cx1_Active; unit SED}, unit=SED, transfer-property=PENDING, to PSCM
          signal LatCtlRampType_D_Rq_oLateralMotionControl_oHS2_CAN: start 53, 2 bit, big-endian, init-value=0, base-type=uint8, compu {0..3=RANGE, 0=Cx0_Slow, 1=Cx1_Medium, 2=Cx2_Fast, 3=Cx3_Immediately; unit SED}, unit=SED, transfer-property=PENDING, to PSCM
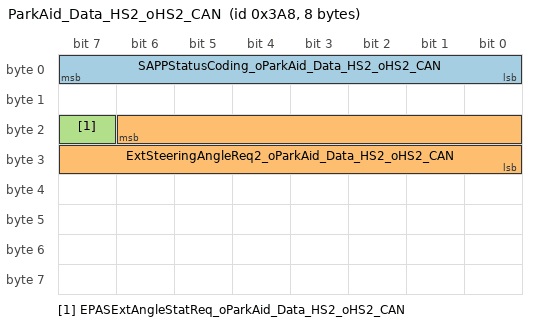
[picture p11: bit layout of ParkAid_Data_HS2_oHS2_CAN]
      frame ParkAid_Data_HS2_oHS2_CAN: id 0x3A8, to PSCM, frame-length=8, can-addressing-mode=STANDARD
        pdu ParkAid_Data_HS2_oHS2_CAN: length=8, minimum-delay=0.01, unused-bit-pattern=0
          signal SAPPStatusCoding_oParkAid_Data_HS2_oHS2_CAN: start 7, 8 bit, big-endian, init-value=0, base-type=uint8, compu {0..255=RANGE; unit unitless}, unit=unitless, transfer-property=PENDING, to PSCM
          signal ExtSteeringAngleReq2_oParkAid_Data_HS2_oHS2_CAN: start 22, 15 bit, big-endian, init-value=0, base-type=uint16, compu {32766=Cx7FFE_Unknown, 32767=Cx7FFF_Invalid, phys=raw*0.1-1000 for raw 0..32767; unit Degrees} "Source signal range: [0,32765]", unit=Degrees, transfer-property=PENDING, to PSCM
          signal EPASExtAngleStatReq_oParkAid_Data_HS2_oHS2_CAN: start 23, 1 bit, big-endian, init-value=0, base-type=boolean, compu {0..1=RANGE, 0=Cx0_NoRequest, 1=Cx1_Request; unit SED}, unit=SED, transfer-property=PENDING, to PSCM
      frame PowertrainData_10_HS2_oHS2_CAN: id 0x176, to PSCM, frame-length=8, can-addressing-mode=STANDARD
        pdu PowertrainData_10_HS2_oHS2_CAN: length=8, minimum-delay=0.02, unused-bit-pattern=0
          signal TrnRng_D_Rq_oPowertrainData_10_HS2_oHS2_CAN: start 27, 4 bit, big-endian, init-value=14, base-type=uint8, compu {0..15=RANGE, 0=Cx0_Park, 1=Cx1_Reverse, 2=Cx2_Neutral, 3=Cx3_Drive, 4=Cx4_Sport_DriveSport_Mposition, 5=Cx5_Low, 6=Cx6_Range1_M1_L1, 7=Cx7_Range2_M2_L2, 8=Cx8_Range3_M3_L3, 9=Cx9_Range4, 10=CxA_Range5, 11=CxB_Range6, 12=CxC_NotUsed_1, 13=CxD_NotUsed_2, 14=CxE_Unknown_Position, 15=CxF_Fault; unit SED}, unit=SED, transfer-property=PENDING, to PSCM
          signal TrnPrkSys_D_Actl_oPowertrainData_10_HS2_oHS2_CAN: start 31, 4 bit, big-endian, init-value=0, base-type=uint8, compu {0..15=RANGE, 0=Cx0_NotKnown, 1=Cx1_Park, 2=Cx2_TransitionCloseToPark, 3=Cx3_AtNoSpring, 4=Cx4_TransitionCloseToOutOfPark, 5=Cx5_OutOfPark, 6=Cx6_Override, 7=Cx7_OutOfRangeLow, 8=Cx8_OutOfRangeHigh, 9=Cx9_FrequencyError, 10=CxA_NotUsed_1, 11=CxB_NotUsed_2, 12=CxC_NotUsed_3, 13=CxD_NotUsed_4, 14=CxE_NotUsed_5, 15=CxF_Faulty; unit SED}, unit=SED, transfer-property=PENDING, to PSCM
      frame PSCM_AutoSar_Network_Mgmt_oHS2_CAN: id 0x5B5, from PSCM, frame-length=8, can-addressing-mode=STANDARD
        nm pdu PSCM_AutoSar_Network_Mgmt_oHS2_CAN: length=8, unused-bit-pattern=0
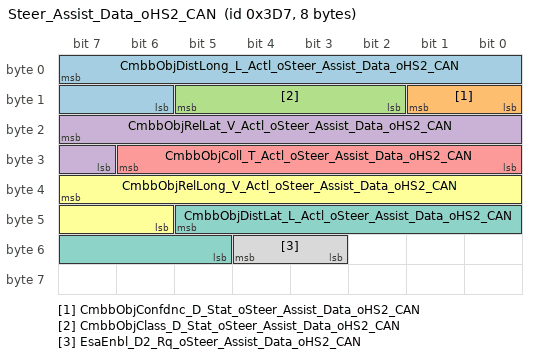
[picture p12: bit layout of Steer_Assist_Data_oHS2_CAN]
      frame Steer_Assist_Data_oHS2_CAN: id 0x3D7, to PSCM, frame-length=8, can-addressing-mode=STANDARD
        pdu Steer_Assist_Data_oHS2_CAN: length=8, minimum-delay=0.02, transmission-mode-false-timing=cyclic-timing={time-offset=0, time-period=0.05}, transmission-mode-true-timing=cyclic-timing={time-offset=0, time-period=0.05}, unused-bit-pattern=0
          signal CmbbObjDistLong_L_Actl_oSteer_Assist_Data_oHS2_CAN: start 7, 10 bit, big-endian, init-value=1022, base-type=uint16, compu {1022=Cx3FE_NoDataExists, 1023=Cx3FF_Faulty, phys=raw*0.1 for raw 0..1023; unit meter} "Source signal range: [0,1021]", unit=meter, transfer-property=PENDING, to PSCM
          signal CmbbObjConfdnc_D_Stat_oSteer_Assist_Data_oHS2_CAN: start 9, 2 bit, big-endian, init-value=0, base-type=uint8, compu {0..3=RANGE, 0=Cx0_NotDetermined, 1=Cx1_Low, 2=Cx2_Medium, 3=Cx3_High; unit SED}, unit=SED, transfer-property=PENDING, to PSCM
          signal CmbbObjClass_D_Stat_oSteer_Assist_Data_oHS2_CAN: start 13, 4 bit, big-endian, init-value=0, base-type=uint8, compu {0..15=RANGE, 0=Cx0_Undetermined, 1=Cx1_Vehicle, 2=Cx2_Motorcycle, 3=Cx3_Truck, 4=Cx4_Pedestrian, 5=Cx5_Bicycle, 6=Cx6_Unclassified_Vehicle, 7=Cx7_NotUsed_1, 8=Cx8_NotUsed_2, 9=Cx9_NotUsed_3, 10=CxA_NotUsed_4, 11=CxB_NotUsed_5, 12=CxC_NotUsed_6, 13=CxD_NotUsed_7, 14=CxE_NotUsed_8, 15=CxF_NotUsed_9; unit SED}, unit=SED, transfer-property=PENDING, to PSCM
          signal CmbbObjRelLat_V_Actl_oSteer_Assist_Data_oHS2_CAN: start 23, 9 bit, big-endian, init-value=510, base-type=uint16, compu {510=Cx1FE_NoDataExists, 511=Cx1FF_Faulty, phys=raw*0.1-25.5 for raw 0..511; unit meters/sec} "Source signal range: [0,509]", unit=meters/sec, transfer-property=PENDING, to PSCM
          signal CmbbObjColl_T_Actl_oSteer_Assist_Data_oHS2_CAN: start 30, 7 bit, big-endian, init-value=126, base-type=uint8, compu {126=Cx7E_NoDataExists, 127=Cx7F_Faulty, phys=raw*0.05 for raw 0..127; unit second} "Source signal range: [0,125]", unit=second, transfer-property=PENDING, to PSCM
          signal CmbbObjRelLong_V_Actl_oSteer_Assist_Data_oHS2_CAN: start 39, 10 bit, big-endian, init-value=1022, base-type=uint16, compu {1022=Cx3FE_NoDataExists, 1023=Cx3FF_Faulty, phys=raw*0.1-102.1 for raw 0..1023; unit meters/sec} "Source signal range: [0,1021]", unit=meters/sec, transfer-property=PENDING, to PSCM
          signal CmbbObjDistLat_L_Actl_oSteer_Assist_Data_oHS2_CAN: start 45, 9 bit, big-endian, init-value=510, base-type=uint16, compu {510=Cx1FE_NoDataExists, 511=Cx1FF_Faulty, phys=raw*0.1-25.5 for raw 0..511; unit meter} "Source signal range: [0,509]", unit=meter, transfer-property=PENDING, to PSCM
          signal EsaEnbl_D2_Rq_oSteer_Assist_Data_oHS2_CAN: start 52, 2 bit, big-endian, init-value=0, base-type=uint8, compu {0..3=RANGE, 0=Cx0_Disabled, 1=Cx1_Pending, 2=Cx2_Enabled, 3=Cx3_NotConfigured; unit SED}, unit=SED, transfer-property=PENDING, to PSCM
      frame Steering_Data_oHS2_CAN: id 0x83, to PSCM, frame-length=8, can-addressing-mode=STANDARD
        pdu Steering_Data_oHS2_CAN: length=8, minimum-delay=0.02, transmission-mode-false-timing={cyclic-timing={time-offset=0, time-period=0.1}, event-controlled-timing={number-of-repetitions=0, repetition-period=0}}, transmission-mode-true-timing={cyclic-timing={time-offset=0, time-period=0.1}, event-controlled-timing={number-of-repetitions=0, repetition-period=0}}, unused-bit-pattern=0
          signal TurnLghtSwtch_D_Stat_oSteering_Data_oHS2_CAN: start 5, 2 bit, big-endian, init-value=0, base-type=uint8, compu {0..3=RANGE, 0=Cx0_Off, 1=Cx1_Left, 2=Cx2_Right, 3=Cx3_Unused_Treat_As_Off; unit SED}, unit=SED, transfer-property=TRIGGERED-ON-CHANGE-WITHOUT-REPETITION, to PSCM
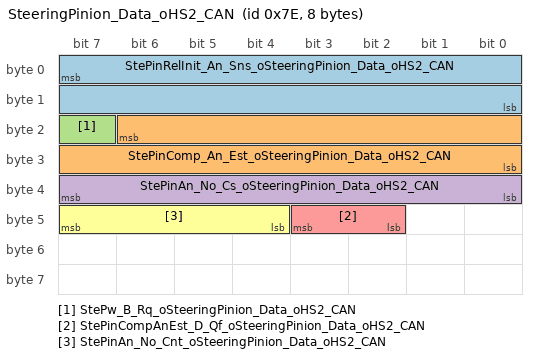
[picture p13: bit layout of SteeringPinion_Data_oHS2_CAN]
      frame SteeringPinion_Data_oHS2_CAN: id 0x7E, from PSCM, frame-length=8, can-addressing-mode=STANDARD
        pdu SteeringPinion_Data_oHS2_CAN: length=8, minimum-delay=0, transmission-mode-false-timing=cyclic-timing={time-offset=0, time-period=0.01}, transmission-mode-true-timing=cyclic-timing={time-offset=0, time-period=0.01}, unused-bit-pattern=0
          signal StePinRelInit_An_Sns_oSteeringPinion_Data_oHS2_CAN: start 7, 16 bit, big-endian, init-value=65535, base-type=uint16, compu {65534=CxFFFE_NoDataExists, 65535=CxFFFF_Faulty, phys=raw*0.1-3200 for raw 0..65535; unit degrees} "Source signal range: [0,65533]", unit=degrees, transfer-property=PENDING  # SASM will transmit these signals on vehicles with SASM and without PSCM. SCCM will not Tx this signal when SASM is present.
          signal StePinComp_An_Est_oSteeringPinion_Data_oHS2_CAN: start 22, 15 bit, big-endian, init-value=16000, base-type=uint16, compu {phys=raw*0.1-1600 for raw 0..32766; unit degrees}, unit=degrees, transfer-property=PENDING
          signal StePw_B_Rq_oSteeringPinion_Data_oHS2_CAN: start 23, 1 bit, big-endian, init-value=0, base-type=boolean, compu {0..1=RANGE, 0=Cx0_No, 1=Cx1_Yes; unit SED}, unit=SED, transfer-property=PENDING
          signal StePinAn_No_Cs_oSteeringPinion_Data_oHS2_CAN: start 39, 8 bit, big-endian, init-value=0, base-type=uint8, compu {0..255=RANGE; unit Unitless}, unit=Unitless, transfer-property=PENDING  # Signal not transmitted on gas variants.
          signal StePinCompAnEst_D_Qf_oSteeringPinion_Data_oHS2_CAN: start 43, 2 bit, big-endian, init-value=1, base-type=uint8, compu {0..3=RANGE, 0=Cx0_Faulty, 1=Cx1_No_Data_Exists, 2=Cx2_Degraded, 3=Cx3_OK; unit SED}, unit=SED, transfer-property=PENDING
          signal StePinAn_No_Cnt_oSteeringPinion_Data_oHS2_CAN: start 47, 4 bit, big-endian, init-value=0, base-type=uint8, compu {0..15=RANGE; unit unitless}, unit=unitless, transfer-property=PENDING
      frame SteeringPinion_Data2_oHS2_CAN: id 0x7F, to PSCM, frame-length=8, can-addressing-mode=STANDARD
        pdu SteeringPinion_Data2_oHS2_CAN: length=8, minimum-delay=0.01, transmission-mode-false-timing=cyclic-timing={time-offset=0, time-period=0.02}, transmission-mode-true-timing=cyclic-timing={time-offset=0, time-period=0.02}, unused-bit-pattern=0
          signal StePinOffst_An_Est_oSteeringPinion_Data2_oHS2_CAN: start 7, 16 bit, big-endian, init-value=65534, base-type=uint16, compu {65534=CxFFFE_NoDataExists, 65535=CxFFFF_Faulty, phys=raw*0.1-3200 for raw 0..65535; unit degrees} "Source signal range: [0,65533]", unit=degrees, transfer-property=PENDING, to PSCM  # SASM will transmit these signals on vehicles with SASM and without PSCM. SCCM will not Tx this signal when SASM is present.
          signal StePinOffst_D_Stat_oSteeringPinion_Data2_oHS2_CAN: start 41, 2 bit, big-endian, init-value=0, base-type=uint8, compu {0..3=RANGE, 0=Cx0_OffsetNotCalculated, 1=Cx1_StoredOffset, 2=Cx2_CoarseOffset, 3=Cx3_FineOffset; unit SED}, unit=SED, transfer-property=PENDING, to PSCM
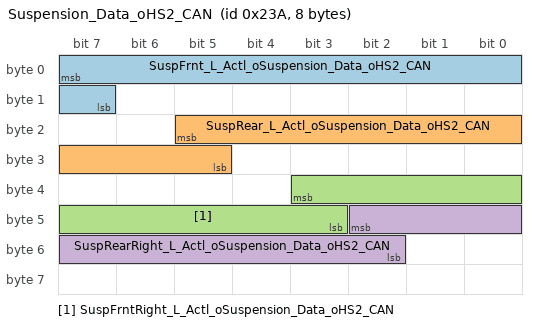
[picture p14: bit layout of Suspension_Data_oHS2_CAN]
      frame Suspension_Data_oHS2_CAN: id 0x23A, to PSCM, frame-length=8, can-addressing-mode=STANDARD
        pdu Suspension_Data_oHS2_CAN: length=8, minimum-delay=0.01, transmission-mode-false-timing=cyclic-timing={time-offset=0, time-period=0.02}, transmission-mode-true-timing=cyclic-timing={time-offset=0, time-period=0.02}, unused-bit-pattern=0
          signal SuspFrnt_L_Actl_oSuspension_Data_oHS2_CAN: start 7, 9 bit, big-endian, init-value=511, base-type=uint16, compu {511=Cx1FF_Fault, phys=raw*0.782779-200 for raw 0..511; unit millimeter} "Source signal range: [0,510]", unit=millimeter, transfer-property=PENDING, to PSCM
          signal SuspRear_L_Actl_oSuspension_Data_oHS2_CAN: start 21, 9 bit, big-endian, init-value=511, base-type=uint16, compu {511=Cx1FF_Fault, phys=raw*0.782779-200 for raw 0..511; unit millimeter} "Source signal range: [0,510]", unit=millimeter, transfer-property=PENDING, to PSCM
          signal SuspFrntRight_L_Actl_oSuspension_Data_oHS2_CAN: start 35, 9 bit, big-endian, init-value=511, base-type=uint16, compu {511=Cx1FF_Faulty, phys=raw*0.782779-200 for raw 0..511; unit millimeter} "Source signal range: [0,510]", unit=millimeter, transfer-property=PENDING, to PSCM
          signal SuspRearRight_L_Actl_oSuspension_Data_oHS2_CAN: start 42, 9 bit, big-endian, init-value=511, base-type=uint16, compu {511=Cx1FF_Faulty, phys=raw*0.782779-200 for raw 0..511; unit millimeter} "Source signal range: [0,510]", unit=millimeter, transfer-property=PENDING, to PSCM
      frame TesterFunctionalReq_H2_oHS2_CAN: id 0x7DF, to PSCM, frame-length=8, can-addressing-mode=STANDARD  # OBDII Request ($7DF) messages are for FNOS 1.0.1 only. Diagnostic Functional Addressing ($7DF) and Dual Rate Periodic messages are for FNOS I3 only.
        n pdu TesterFunctionalReq_H2_Tp_oHS2_CAN: length=8
      frame TesterPhysicalReqPSCM_oHS2_CAN: id 0x730, to PSCM, frame-length=8, can-addressing-mode=STANDARD
        n pdu TesterPhysicalReqPSCM_Tp_oHS2_CAN: length=8
      frame TesterPhysicalResPSCM_oHS2_CAN: id 0x738, from PSCM, frame-length=8, can-addressing-mode=STANDARD
        n pdu TesterPhysicalResPSCM_Tp_oHS2_CAN: length=8
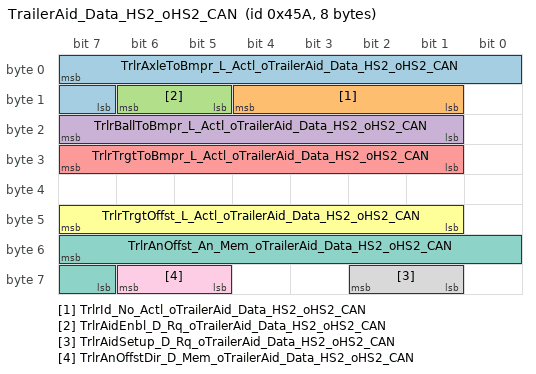
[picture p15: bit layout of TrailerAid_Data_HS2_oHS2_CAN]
      frame TrailerAid_Data_HS2_oHS2_CAN: id 0x45A, to PSCM, frame-length=8, can-addressing-mode=STANDARD
        pdu TrailerAid_Data_HS2_oHS2_CAN: length=8, minimum-delay=0.02, unused-bit-pattern=0
          signal TrlrAxleToBmpr_L_Actl_oTrailerAid_Data_HS2_oHS2_CAN: start 7, 9 bit, big-endian, init-value=0, base-type=uint16, compu {phys=raw*0.0254 for raw 0..511; unit meter}, unit=meter, transfer-property=PENDING, to PSCM
          signal TrlrId_No_Actl_oTrailerAid_Data_HS2_oHS2_CAN: start 12, 4 bit, big-endian, init-value=0, base-type=uint8, compu {0..15=RANGE; unit unitless}, unit=unitless, transfer-property=PENDING, to PSCM
          signal TrlrAidEnbl_D_Rq_oTrailerAid_Data_HS2_oHS2_CAN: start 14, 2 bit, big-endian, init-value=0, base-type=uint8, compu {0..3=RANGE, 0=Cx0_Inactive, 1=Cx1_ActivateTba, 2=Cx2_DeactivateTba, 3=Cx3_NotAvailable; unit SED}, unit=SED, transfer-property=PENDING, to PSCM
          signal TrlrBallToBmpr_L_Actl_oTrailerAid_Data_HS2_oHS2_CAN: start 23, 7 bit, big-endian, init-value=0, base-type=uint8, compu {phys=raw*0.0127 for raw 0..127; unit meter}, unit=meter, transfer-property=PENDING, to PSCM
          signal TrlrTrgtToBmpr_L_Actl_oTrailerAid_Data_HS2_oHS2_CAN: start 31, 7 bit, big-endian, init-value=0, base-type=uint8, compu {phys=raw*0.0127 for raw 0..127; unit meter}, unit=meter, transfer-property=PENDING, to PSCM
          signal TrlrTrgtOffst_L_Actl_oTrailerAid_Data_HS2_oHS2_CAN: start 47, 7 bit, big-endian, init-value=0, base-type=uint8, compu {phys=raw*0.0127 for raw 0..127; unit meter}, unit=meter, transfer-property=PENDING, to PSCM
          signal TrlrAnOffst_An_Mem_oTrailerAid_Data_HS2_oHS2_CAN: start 55, 9 bit, big-endian, init-value=0, base-type=uint16, compu {phys=raw*0.1 for raw 0..511; unit degrees}, unit=degrees, transfer-property=PENDING, to PSCM
          signal TrlrAidSetup_D_Rq_oTrailerAid_Data_HS2_oHS2_CAN: start 58, 2 bit, big-endian, init-value=0, base-type=uint8, compu {0..3=RANGE, 0=Cx0_Inactive, 1=Cx1_BeginSetup, 2=Cx2_EndSetup, 3=Cx3_ConfirmSetup; unit SED}, unit=SED, transfer-property=PENDING, to PSCM
          signal TrlrAnOffstDir_D_Mem_oTrailerAid_Data_HS2_oHS2_CAN: start 62, 2 bit, big-endian, init-value=0, base-type=uint8, compu {0..3=RANGE, 0=Cx0_Null, 1=Cx1_Left_or_Center, 2=Cx2_Right, 3=Cx3_NotUSed; unit SED}, unit=SED, transfer-property=PENDING, to PSCM
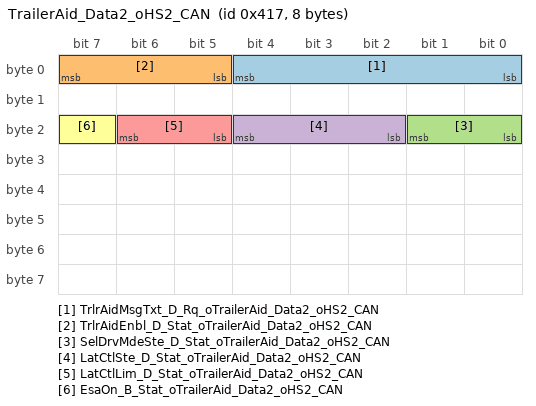
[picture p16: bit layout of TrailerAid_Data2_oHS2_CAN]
      frame TrailerAid_Data2_oHS2_CAN: id 0x417, from PSCM, frame-length=8, can-addressing-mode=STANDARD
        pdu TrailerAid_Data2_oHS2_CAN: length=8, minimum-delay=0.02, transmission-mode-false-timing={cyclic-timing={time-offset=0, time-period=1}, event-controlled-timing={number-of-repetitions=0, repetition-period=0}}, transmission-mode-true-timing={cyclic-timing={time-offset=0, time-period=1}, event-controlled-timing={number-of-repetitions=0, repetition-period=0}}, unused-bit-pattern=0
          signal TrlrAidMsgTxt_D_Rq_oTrailerAid_Data2_oHS2_CAN: start 4, 5 bit, big-endian, init-value=0, base-type=uint8, compu {0..31=RANGE, 0=Cx00_NoMessage, 1=Cx01_Message1, 2=Cx02_Message2, 3=Cx03_Message3, 4=Cx04_Message4, 5=Cx05_Message5, 6=Cx06_Message6, 7=Cx07_Message7, 8=Cx08_Message8, 9=Cx09_Message9, 10=Cx0A_Message10, 11=Cx0B_Message11, 12=Cx0C_Message12, 13=Cx0D_Message13, 14=Cx0E_Message14, 15=Cx0F_Message15, 16=Cx10_Message16, 17=Cx11_Message17, 18=Cx12_Message18, 19=Cx13_Message19, 20=Cx14_Message20, 21=Cx15_Message21, 22=Cx16_Message22, 23=Cx17_Message23, 24=Cx18_Message24, 25=Cx19_Message25, 26=Cx1A_Message26, 27=Cx1B_Message27, 28=Cx1C_Message28, 29=Cx1D_Message29, 30=Cx1E_Message30, 31=Cx1F_Message31; unit SED}, unit=SED, transfer-property=TRIGGERED-ON-CHANGE-WITHOUT-REPETITION
          signal TrlrAidEnbl_D_Stat_oTrailerAid_Data2_oHS2_CAN: start 7, 3 bit, big-endian, init-value=0, base-type=uint8, compu {0..7=RANGE, 0=Cx0_Null, 1=Cx1_TbaActive, 2=Cx2_TbaStandby, 3=Cx3_TbaNotAvailable, 4=Cx4_TbaTadMonitor, 5=Cx5_TbaRecalibrate, 6=Cx6_NoDataExists, 7=Cx7_Faulty; unit SED}, unit=SED, transfer-property=TRIGGERED-ON-CHANGE-WITHOUT-REPETITION
          signal SelDrvMdeSte_D_Stat_oTrailerAid_Data2_oHS2_CAN: start 17, 2 bit, big-endian, init-value=0, base-type=uint8, compu {0..3=RANGE, 0=Cx0_NotAvailable, 1=Cx1_Available, 2=Cx2_TemporarilyNotAvailable, 3=Cx3_Faulty; unit SED}, unit=SED, transfer-property=TRIGGERED-ON-CHANGE-WITHOUT-REPETITION
          signal LatCtlSte_D_Stat_oTrailerAid_Data2_oHS2_CAN: start 20, 3 bit, big-endian, init-value=0, base-type=uint8, compu {0..7=RANGE, 0=Cx0_Unavailable, 1=Cx1_Available, 2=Cx2_ContLatControlInProgress, 3=Cx3_RampOut, 4=Cx4_Denied, 5=Cx5_NotUsed1, 6=Cx6_NotUsed2, 7=Cx7_NotUsed3; unit SED}, unit=SED, transfer-property=TRIGGERED-ON-CHANGE-WITHOUT-REPETITION
          signal LatCtlLim_D_Stat_oTrailerAid_Data2_oHS2_CAN: start 22, 2 bit, big-endian, init-value=0, base-type=uint8, compu {0..3=RANGE, 0=Cx0_LimitNotReached, 1=Cx1_LimitClose, 2=Cx2_LimitReached, 3=Cx3_NotUsed1; unit SED}, unit=SED, transfer-property=TRIGGERED-ON-CHANGE-WITHOUT-REPETITION
          signal EsaOn_B_Stat_oTrailerAid_Data2_oHS2_CAN: start 23, 1 bit, big-endian, init-value=1, base-type=boolean, compu {0..1=RANGE, 0=Cx0_Off, 1=Cx1_On; unit SED}, unit=SED, transfer-property=TRIGGERED-ON-CHANGE-WITHOUT-REPETITION
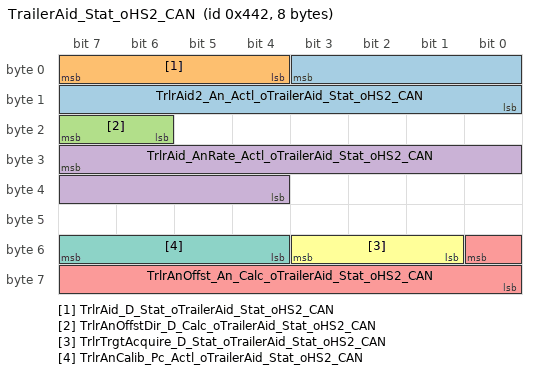
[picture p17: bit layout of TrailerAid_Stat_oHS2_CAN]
      frame TrailerAid_Stat_oHS2_CAN: id 0x442, to PSCM, frame-length=8, can-addressing-mode=STANDARD
        pdu TrailerAid_Stat_oHS2_CAN: length=8, minimum-delay=0.02, transmission-mode-false-timing=cyclic-timing={time-offset=0, time-period=0.05}, transmission-mode-true-timing=cyclic-timing={time-offset=0, time-period=0.05}, unused-bit-pattern=0
          signal TrlrAid2_An_Actl_oTrailerAid_Stat_oHS2_CAN: start 3, 12 bit, big-endian, init-value=900, base-type=uint16, compu {4095=CxFFF_Faulty, phys=raw*0.1-90 for raw 0..4095; unit degrees} "Source signal range: [0,4094]", unit=degrees, transfer-property=PENDING, to PSCM
          signal TrlrAid_D_Stat_oTrailerAid_Stat_oHS2_CAN: start 7, 4 bit, big-endian, init-value=0, base-type=uint8, compu {0..15=RANGE, 0=Cx0_Target_Not_Acquired, 1=Cx1_Init, 2=Cx2_Trgt_Acqrd_Confidence_Low, 3=Cx3_Trgt_Acqrd_Confidence_Med, 4=Cx4_Trgt_Acqrd_Confidence_High, 5=Cx5_Invalid_Parameters, 6=Cx6_Target_Cannot_Be_Located, 7=Cx7_Sensor_Blocked, 8=Cx8_No_Video_Input, 9=Cx9_Insufficient_Lighting, 10=CxA_Trgt_Acqrd_Conf_Low_w_Par, 11=CxB_Trgt_Acqrd_Conf_Med_w_Par, 12=CxC_Trgt_Acqrd_Conf_High_w_Par, 13=CxD_TAD_Rq_Denied, 14=CxE_Trgt_Acqrd_Conf_Unk_w_Par, 15=CxF_Faulty; unit SED}, unit=SED, transfer-property=PENDING, to PSCM
          signal TrlrAnOffstDir_D_Calc_oTrailerAid_Stat_oHS2_CAN: start 23, 2 bit, big-endian, init-value=0, base-type=uint8, compu {0..3=RANGE, 0=Cx0_Null, 1=Cx1_Left_or_Center, 2=Cx2_Right, 3=Cx3_NotUSed; unit SED}, unit=SED, transfer-property=PENDING, to PSCM
          signal TrlrAid_AnRate_Actl_oTrailerAid_Stat_oHS2_CAN: start 31, 12 bit, big-endian, init-value=500, base-type=uint16, compu {4095=CxFFF_Faulty, phys=raw*0.1-50 for raw 0..4095; unit degrees/sec} "Source signal range: [0,4094]", unit=degrees/sec, transfer-property=PENDING, to PSCM
          signal TrlrAnOffst_An_Calc_oTrailerAid_Stat_oHS2_CAN: start 48, 9 bit, big-endian, init-value=0, base-type=uint16, compu {phys=raw*0.1 for raw 0..511; unit degrees}, unit=degrees, transfer-property=PENDING, to PSCM
          signal TrlrTrgtAcquire_D_Stat_oTrailerAid_Stat_oHS2_CAN: start 51, 3 bit, big-endian, init-value=0, base-type=uint8, compu {0..7=RANGE, 0=Cx0_Null, 1=Cx1_TargetAcquired, 2=Cx2_TargetNotAcquired, 3=Cx3_Processing, 4=Cx4_RVCforTBA_Activated, 5=Cx5_NotUsed_1, 6=Cx6_NotUsed_2, 7=Cx7_Faulty; unit SED}, unit=SED, transfer-property=PENDING, to PSCM
          signal TrlrAnCalib_Pc_Actl_oTrailerAid_Stat_oHS2_CAN: start 55, 4 bit, big-endian, init-value=0, base-type=uint8, compu {15=CxF_Faulty, phys=raw*10 for raw 0..15; unit percent} "Source signal range: [0,14]", unit=percent, transfer-property=PENDING, to PSCM
      frame TrailerBrakeInfo_oHS2_CAN: id 0x445, to PSCM, frame-length=8, can-addressing-mode=STANDARD
        pdu TrailerBrakeInfo_oHS2_CAN: length=8, minimum-delay=0.02, transmission-mode-false-timing=cyclic-timing={time-offset=0, time-period=0.1}, transmission-mode-true-timing=cyclic-timing={time-offset=0, time-period=0.1}, unused-bit-pattern=0
          signal TrlrBrkActCnnct_B_Actl_oTrailerBrakeInfo_oHS2_CAN: start 6, 1 bit, big-endian, init-value=0, base-type=boolean, compu {0..1=RANGE, 0=Cx0_No, 1=Cx1_Yes; unit SED}, unit=SED, transfer-property=PENDING, to PSCM
      frame TrailerInfo_HS2_oHS2_CAN: id 0x443, to PSCM, frame-length=8, can-addressing-mode=STANDARD
        pdu TrailerInfo_HS2_oHS2_CAN: length=8, minimum-delay=0.02, unused-bit-pattern=0
          signal TrlrLampCnnct_B_Actl_oTrailerInfo_HS2_oHS2_CAN: start 7, 1 bit, big-endian, init-value=0, base-type=boolean, compu {0..1=RANGE, 0=Cx0_No, 1=Cx1_Yes; unit SED}, unit=SED, transfer-property=PENDING, to PSCM
      frame TransGearData_HS2_oHS2_CAN: id 0x230, to PSCM, frame-length=8, can-addressing-mode=STANDARD
        pdu TransGearData_HS2_oHS2_CAN: length=8, minimum-delay=0.01, transmission-mode-false-timing={cyclic-timing={time-offset=0, time-period=0.1}, event-controlled-timing={number-of-repetitions=0, repetition-period=0}}, transmission-mode-true-timing={cyclic-timing={time-offset=0, time-period=0.1}, event-controlled-timing={number-of-repetitions=0, repetition-period=0}}, unused-bit-pattern=0
          signal GearLvrPos_D_Actl_oTransGearData_HS2_oHS2_CAN: start 12, 4 bit, big-endian, init-value=14, base-type=uint8, compu {0..15=RANGE, 0=Cx0_Park, 1=Cx1_Reverse, 2=Cx2_Neutral, 3=Cx3_Drive, 4=Cx4_Sport_DriveSport, 5=Cx5_Low, 6=Cx6_first, 7=Cx7_second, 8=Cx8_third, 9=Cx9_fourth, 10=CxA_fifth, 11=CxB_sixth, 12=CxC_Undefined_Treat_as_Fault, 13=CxD_Undefined_Treat_as_Fault (Undefined_Treat_as__Fault), 14=CxE_Unknown_Position, 15=CxF_Fault; unit SED}, unit=SED, transfer-property=TRIGGERED-ON-CHANGE-WITHOUT-REPETITION, to PSCM
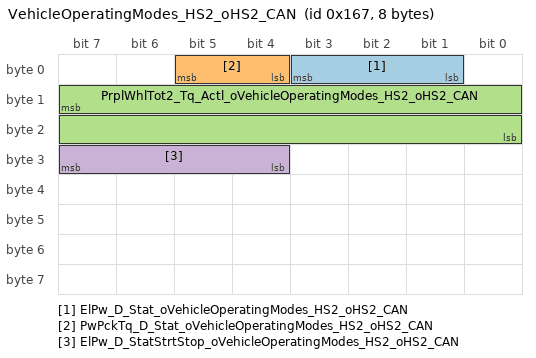
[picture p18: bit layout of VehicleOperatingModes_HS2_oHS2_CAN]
      frame VehicleOperatingModes_HS2_oHS2_CAN: id 0x167, to PSCM, frame-length=8, can-addressing-mode=STANDARD
        pdu VehicleOperatingModes_HS2_oHS2_CAN: length=8, minimum-delay=0.02, unused-bit-pattern=0
          signal ElPw_D_Stat_oVehicleOperatingModes_HS2_oHS2_CAN: start 3, 3 bit, big-endian, init-value=0, base-type=uint8, compu {0..7=RANGE, 0=Cx0_Not_Supported, 1=Cx1_Supported, 2=Cx2_Not_Supported_Imminent, 3=Cx3_LV_Event_In_Progress, 4=Cx4_Fault_Limited, 5=Cx5_NotUsed_1, 6=Cx6_NotUsed_2, 7=Cx7_NotUsed_3; unit SED}, unit=SED, transfer-property=PENDING, to PSCM
          signal PwPckTq_D_Stat_oVehicleOperatingModes_HS2_oHS2_CAN: start 5, 2 bit, big-endian, init-value=0, base-type=uint8, compu {0..3=RANGE, 0=Cx0_PwPckOff_TqNotAvailable, 1=Cx1_PwPckOn_TqNotAvailable, 2=Cx2_StartInPrgrss_TqNotAvail, 3=Cx3_PwPckOn_TqAvailable; unit SED}, unit=SED, transfer-property=PENDING, to PSCM
          signal PrplWhlTot2_Tq_Actl_oVehicleOperatingModes_HS2_oHS2_CAN: start 15, 16 bit, big-endian, init-value=0, base-type=uint16, compu {65534=CxFFFE_NoDataExists, 65535=CxFFFF_Fault, phys=raw*4-131072 for raw 0..65535; unit Nm} "Source signal range: [0,65533]", unit=Nm, transfer-property=PENDING, to PSCM
          signal ElPw_D_StatStrtStop_oVehicleOperatingModes_HS2_oHS2_CAN: start 31, 4 bit, big-endian, init-value=0, base-type=uint8, compu {0..15=RANGE, 0=Cx0_Not_Supported, 1=Cx1_Supported_All, 2=Cx2_Not_Supported_Imminent, 3=Cx3_LV_Event_in_Progress, 4=Cx4_Fault_Limited, 5=Cx5_Limited_Support, 6=Cx6_Supported_Level_1, 7=Cx7_Supported_Level_2, 8=Cx8_Supported_Level_3, 9=Cx9_Supported_Level_4, 10=CxA_NotUsed1, 11=CxB_NotUsed2, 12=CxC_NotUsed3, 13=CxD_NotUsed4, 14=CxE_NotUsed5, 15=CxF_NotUsed6; unit SED}, unit=SED, transfer-property=PENDING, to PSCM
      frame VeyDynamics_Data_oHS2_CAN: id 0x345, to PSCM, frame-length=8, can-addressing-mode=STANDARD
        pdu VeyDynamics_Data_oHS2_CAN: length=8, minimum-delay=0.02, transmission-mode-false-timing={cyclic-timing={time-offset=0, time-period=1}, event-controlled-timing={number-of-repetitions=0, repetition-period=0}}, transmission-mode-true-timing={cyclic-timing={time-offset=0, time-period=1}, event-controlled-timing={number-of-repetitions=0, repetition-period=0}}, unused-bit-pattern=0
          signal CcdMsgTxt_D_RqDsply_oVeyDynamics_Data_oHS2_CAN: start 7, 4 bit, big-endian, init-value=0, base-type=uint8, compu {0..15=RANGE, 0=Cx0_No_Mode_Selected, 1=Cx1_Comfort, 2=Cx2_Normal, 3=Cx3_Sport, 4=Cx4_Fault, 5=Cx5_CCD_Service_Required, 6=Cx6_CCD_Temporarily_Off, 7=Cx7_Mode_Change_Unavailable, 8=Cx8_Unused1, 9=Cx9_Unused2, 10=CxA_Unused3, 11=CxB_Unused4, 12=CxC_Unused5, 13=CxD_Unused6, 14=CxE_Unused7, 15=CxF_Unused8; unit SED}, unit=SED, transfer-property=TRIGGERED-ON-CHANGE-WITHOUT-REPETITION, to PSCM
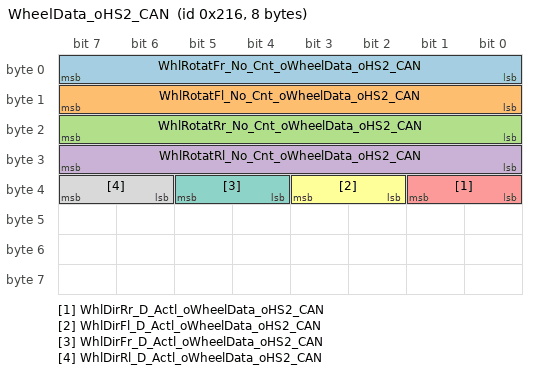
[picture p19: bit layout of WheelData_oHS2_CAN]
      frame WheelData_oHS2_CAN: id 0x216, to PSCM, frame-length=8, can-addressing-mode=STANDARD
        pdu WheelData_oHS2_CAN: length=8, minimum-delay=0.01, transmission-mode-false-timing=cyclic-timing={time-offset=0, time-period=0.02}, transmission-mode-true-timing=cyclic-timing={time-offset=0, time-period=0.02}, unused-bit-pattern=0
          signal WhlRotatFr_No_Cnt_oWheelData_oHS2_CAN: start 7, 8 bit, big-endian, init-value=0, base-type=uint8, compu {0..255=RANGE; unit Unitless}, unit=Unitless, transfer-property=PENDING, to PSCM  # DCR 1833 to update Tx from GWM to EP100ms. Wheel Count signals are used by complex algorithm to determine Tire Pressure by Location & can't change from 20msec. (jweinfur)
          signal WhlRotatFl_No_Cnt_oWheelData_oHS2_CAN: start 15, 8 bit, big-endian, init-value=0, base-type=uint8, compu {0..255=RANGE; unit Unitless}, unit=Unitless, transfer-property=PENDING, to PSCM  # DCR 1833 to update Tx from GWM to EP100ms. Wheel Count signals are used by complex algorithm to determine Tire Pressure by Location & can't change from 20msec. (jweinfur)
          signal WhlRotatRr_No_Cnt_oWheelData_oHS2_CAN: start 23, 8 bit, big-endian, init-value=0, base-type=uint8, compu {0..255=RANGE; unit Unitless}, unit=Unitless, transfer-property=PENDING, to PSCM  # DCR 1833 to update Tx from GWM to EP100ms. Wheel Count signals are used by complex algorithm to determine Tire Pressure by Location & can't change from 20msec. (jweinfur)
          signal WhlRotatRl_No_Cnt_oWheelData_oHS2_CAN: start 31, 8 bit, big-endian, init-value=0, base-type=uint8, compu {0..255=RANGE; unit Unitless}, unit=Unitless, transfer-property=PENDING, to PSCM  # DCR 1833 to update Tx from GWM to EP100ms. Wheel Count signals are used by complex algorithm to determine Tire Pressure by Location & can't change from 20msec. (jweinfur)
          signal WhlDirRr_D_Actl_oWheelData_oHS2_CAN: start 33, 2 bit, big-endian, init-value=0, base-type=uint8, compu {0..3=RANGE, 0=Cx0_Forward, 1=Cx1_Backward, 2=Cx2_Unknown, 3=Cx3_Failed; unit SED}, unit=SED, transfer-property=PENDING, to PSCM
          signal WhlDirFl_D_Actl_oWheelData_oHS2_CAN: start 35, 2 bit, big-endian, init-value=0, base-type=uint8, compu {0..3=RANGE, 0=Cx0_Forward, 1=Cx1_Backward, 2=Cx2_Unknown, 3=Cx3_Failed; unit SED}, unit=SED, transfer-property=PENDING, to PSCM
          signal WhlDirFr_D_Actl_oWheelData_oHS2_CAN: start 37, 2 bit, big-endian, init-value=0, base-type=uint8, compu {0..3=RANGE, 0=Cx0_Forward, 1=Cx1_Backward, 2=Cx2_Unknown, 3=Cx3_Failed; unit SED}, unit=SED, transfer-property=PENDING, to PSCM
          signal WhlDirRl_D_Actl_oWheelData_oHS2_CAN: start 39, 2 bit, big-endian, init-value=0, base-type=uint8, compu {0..3=RANGE, 0=Cx0_Forward, 1=Cx1_Backward, 2=Cx2_Unknown, 3=Cx3_Failed; unit SED}, unit=SED, transfer-property=PENDING, to PSCM
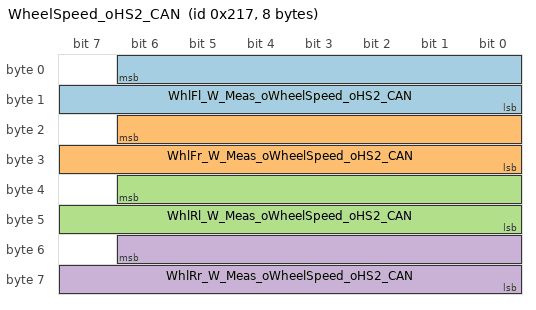
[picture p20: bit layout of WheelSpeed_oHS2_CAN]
      frame WheelSpeed_oHS2_CAN: id 0x217, to PSCM, frame-length=8, can-addressing-mode=STANDARD
        pdu WheelSpeed_oHS2_CAN: length=8, minimum-delay=0, transmission-mode-false-timing=cyclic-timing={time-offset=0, time-period=0.01}, transmission-mode-true-timing=cyclic-timing={time-offset=0, time-period=0.01}, unused-bit-pattern=0
          signal WhlFl_W_Meas_oWheelSpeed_oHS2_CAN: start 6, 15 bit, big-endian, init-value=0, base-type=uint16, compu {32766=Cx7FFE_Unknown, 32767=Cx7FFF_Fault, phys=raw*0.01 for raw 0..32767; unit rad/s} "Source signal range: [0,32765]", unit=rad/s, transfer-property=PENDING, to PSCM
          signal WhlFr_W_Meas_oWheelSpeed_oHS2_CAN: start 22, 15 bit, big-endian, init-value=0, base-type=uint16, compu {32766=Cx7FFE_Unknown, 32767=Cx7FFF_Fault, phys=raw*0.01 for raw 0..32767; unit rad/s} "Source signal range: [0,32765]", unit=rad/s, transfer-property=PENDING, to PSCM
          signal WhlRl_W_Meas_oWheelSpeed_oHS2_CAN: start 38, 15 bit, big-endian, init-value=0, base-type=uint16, compu {32766=Cx7FFE_Unknown, 32767=Cx7FFF_Fault, phys=raw*0.01 for raw 0..32767; unit rad/s} "Source signal range: [0,32765]", unit=rad/s, transfer-property=PENDING, to PSCM
          signal WhlRr_W_Meas_oWheelSpeed_oHS2_CAN: start 54, 15 bit, big-endian, init-value=0, base-type=uint16, compu {32766=Cx7FFE_Unknown, 32767=Cx7FFF_Fault, phys=raw*0.01 for raw 0..32767; unit rad/s} "Source signal range: [0,32765]", unit=rad/s, transfer-property=PENDING, to PSCM
      frame Yaw_Data_oHS2_CAN: id 0x91, to PSCM, frame-length=8, can-addressing-mode=STANDARD
        pdu Yaw_Data_oHS2_CAN: length=8, minimum-delay=0, transmission-mode-false-timing=cyclic-timing={time-offset=0, time-period=0.01}, transmission-mode-true-timing=cyclic-timing={time-offset=0, time-period=0.01}, unused-bit-pattern=0
          signal VehRol_W_Actl_oYaw_Data_oHS2_CAN: start 7, 16 bit, big-endian, init-value=65534, base-type=uint16, compu {65534=CxFFFE_NoDataExists, 65535=CxFFFF_Faulty, phys=raw*0.0002-6.5 for raw 0..65535; unit rad/s} "Source signal range: [0,65533]", unit=rad/s, transfer-property=PENDING, to PSCM
          signal VehYaw_W_Actl_oYaw_Data_oHS2_CAN: start 23, 16 bit, big-endian, init-value=65534, base-type=uint16, compu {65534=CxFFFE_NoDataExists, 65535=CxFFFF_Faulty, phys=raw*0.0002-6.5 for raw 0..65535; unit rad/s} "Source signal range: [0,65533]", unit=rad/s, transfer-property=PENDING, to PSCM  # CCMGenSigTimeoutTime=1000
      pdu triggering PT_DeliveryVersion: pdu=DeliveryVersion_oHS2_CAN, to PSCM
      pdu triggering PT_FileVersion: pdu=FileVersion_oHS2_CAN, to PSCM
      pdu triggering PT_TesterFunctionalReq_H2: pdu=TesterFunctionalReq_H2_oHS2_CAN, to PSCM
      pdu triggering PT_TesterPhysicalReqPSCM: pdu=TesterPhysicalReqPSCM_oHS2_CAN, to PSCM
      pdu triggering PT_TesterPhysicalResPSCM: pdu=TesterPhysicalResPSCM_oHS2_CAN, from PSCM
package /ECU
  ecu instance PSCM: associated-com-i-pdu-group=[PSCM_oHS2_CAN_Rx, PSCM_oHS2_CAN_Tx]  # Power Steering Control Module, Variable Assist Power Steering (VAPS)
    can communication controller CT_HS2_CAN
    can communication connector CN_HS2_CAN: comm-controller=CT_HS2_CAN
package /IPDUGroup
  i signal i pdu group PSCM_oHS2_CAN_Rx: communication-direction=IN
    i-signal-i-pdus:
      ABS_BrkBst_Data_oHS2_CAN
      Accel_Data_oHS2_CAN
      ActiveFrontSteering_Stat2_oHS2_CAN
      Battery_Mgmt_2_HS2_oHS2_CAN
      Body_Info_4_HS2_oHS2_CAN
      BodyEngGateway_2_HS2_oHS2_CAN
      BodyInfo_3_HS2_oHS2_CAN
      BrakeSnData_{3..5}_oHS2_CAN
      BrakeSysFeatures_2_oHS2_CAN
      BrakeSysFeatures_3_oHS2_CAN
      BrakeSysFeatures_oHS2_CAN
      Cluster_Info1_HS2_oHS2_CAN
      DeliveryVersion_oHS2_CAN
      DesiredTorqBrk_oHS2_CAN
      Driveline_Data_1_oHS2_CAN
      EngBrakeData_HS2_oHS2_CAN
      EngineData_9_HS2_oHS2_CAN
      EngVehicleSpThrottle_HS2_oHS2_CAN
      EngVehicleSpThrottle2_HS2_oHS2_CAN
      FileVersion_oHS2_CAN
      GatewayData_HS2_oHS2_CAN
      GatewayData3_HS2_oHS2_CAN
      GGCC_Config_Mgmt_ID_1_HS2_oHS2_CAN
      Lane_Assist_Data1_oHS2_CAN
      LateralMotionControl_oHS2_CAN
      ParkAid_Data_HS2_oHS2_CAN
      PowertrainData_10_HS2_oHS2_CAN
      Steer_Assist_Data_oHS2_CAN
      Steering_Data_oHS2_CAN
      SteeringPinion_Data2_oHS2_CAN
      Suspension_Data_oHS2_CAN
      TrailerAid_Data_HS2_oHS2_CAN
      TrailerAid_Stat_oHS2_CAN
      TrailerBrakeInfo_oHS2_CAN
      TrailerInfo_HS2_oHS2_CAN
      TransGearData_HS2_oHS2_CAN
      VehicleOperatingModes_HS2_oHS2_CAN
      VeyDynamics_Data_oHS2_CAN
      WheelData_oHS2_CAN
      WheelSpeed_oHS2_CAN
      Yaw_Data_oHS2_CAN
  i signal i pdu group PSCM_oHS2_CAN_Tx: communication-direction=OUT, i-signal-i-pdus=[EPAS_INFO_oHS2_CAN, Lane_Assist_Data3_oHS2_CAN, SteeringPinion_Data_oHS2_CAN, TrailerAid_Data2_oHS2_CAN]
package /PDU
  pdu DeliveryVersion_oHS2_CAN: length=10, unused-bit-pattern=0
    signal DeliverySipNumber_oDeliveryVersion_oHS2_CAN: start 0, 24 bit, little-endian, init-value=1507332, base-type=uint32, to PSCM
    signal DeliverySubProjectNumber_oDeliveryVersion_oHS2_CAN: start 24, 32 bit, little-endian, init-value=23072854, base-type=uint32, to PSCM
    signal DeliveryNumber_oDeliveryVersion_oHS2_CAN: start 56, 8 bit, little-endian, init-value=0, base-type=uint8, to PSCM
    signal DeliveryIdle_oDeliveryVersion_oHS2_CAN: start 64, 16 bit, little-endian, init-value=0, base-type=uint16, to PSCM
  pdu FileVersion_oHS2_CAN: length=4, unused-bit-pattern=0
    signal FileVersionYear_oFileVersion_oHS2_CAN: start 0, 8 bit, little-endian, init-value=22, base-type=uint8, to PSCM
    signal FileVersionMonth_oFileVersion_oHS2_CAN: start 8, 8 bit, little-endian, init-value=5, base-type=uint8, to PSCM
    signal FileVersionDay_oFileVersion_oHS2_CAN: start 16, 8 bit, little-endian, init-value=24, base-type=uint8, to PSCM
    signal FileVersionNumber_oFileVersion_oHS2_CAN: start 24, 8 bit, little-endian, init-value=5, base-type=uint8, to PSCM
  dcm i pdu TesterFunctionalReq_H2_oHS2_CAN: length=7, diag-pdu-type=DIAG-REQUEST
  dcm i pdu TesterPhysicalReqPSCM_oHS2_CAN: length=8, diag-pdu-type=DIAG-REQUEST
  dcm i pdu TesterPhysicalResPSCM_oHS2_CAN: length=8, diag-pdu-type=DIAG-RESPONSE
package /DataType
  base type uint8_8_iso_8859_1: category=FIXED_LENGTH, base-type-size=64, base-type-encoding=ISO-8859-1
package /DataType/Unit
  30 x unit:
    U_1Ym: display-name=1/m
    U_1Ymeter: display-name=1/meter
    U_Amps: display-name=Amps
    U_deg: display-name=deg
    U_degrees: display-name=degrees
    U_Degrees: display-name=Degrees
    U_Degrees_C: display-name=Degrees C
    U_degreesYsec: display-name=degrees/sec
    U_degYs: display-name=deg/s
    U_km: display-name=km
    U_kmYh: display-name=km/h
    U_kph: display-name=kph
    U_meter: display-name=meter
    U_metersYsec: display-name=meters/sec
    U_millimeter: display-name=millimeter
    U_mixed: display-name=mixed
    U_mrad: display-name=mrad
    U_mYsX2: display-name=m/s^2
    U_Nm: display-name=Nm
    U_p: display-name=%
    U_percent: display-name=percent
    U_radians: display-name=radians
    U_radYs: display-name=rad/s
    U_rpm: display-name=rpm
    U_second: display-name=second
    U_SED: display-name=SED
    U_volt: display-name=volt
    U_Volts: display-name=Volts
    unitless: display-name=unitless
    Unitless: display-name=Unitless
